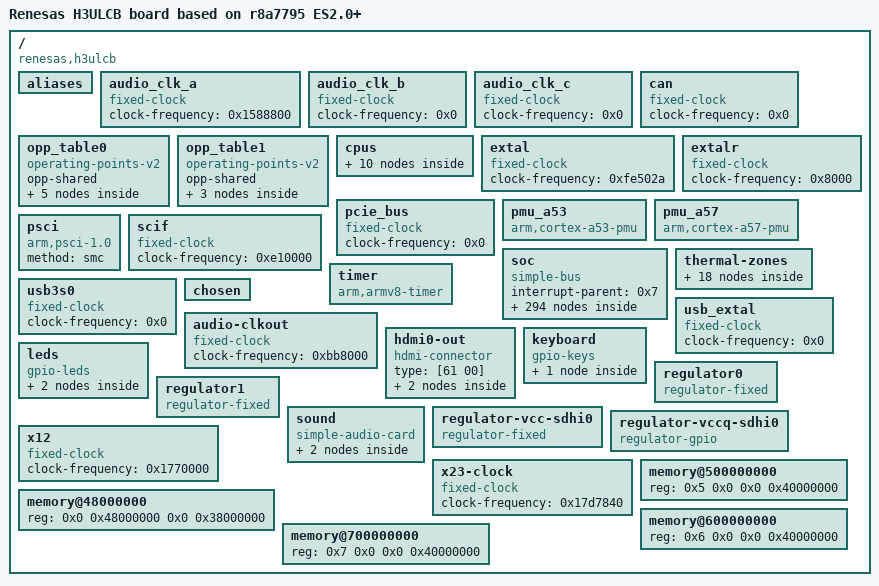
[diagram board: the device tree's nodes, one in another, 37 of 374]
/*
 * The code contained herein is licensed under the GNU General Public
 * License. You may obtain a copy of the GNU General Public License
 * Version 2 or later at the following locations:
 *
 * http://www.opensource.org/licenses/gpl-license.html
 * http://www.gnu.org/copyleft/gpl.html
 *
 * @TAG(OTHER_GPL)
 */

/dts-v1/;

/ {
	compatible = "renesas,h3ulcb", "renesas,r8a7795";
	#address-cells = <0x2>;
	#size-cells = <0x2>;
	model = "Renesas H3ULCB board based on r8a7795 ES2.0+";

	aliases {
		i2c0 = "/soc/i2c@e6500000";
		i2c1 = "/soc/i2c@e6508000";
		i2c2 = "/soc/i2c@e6510000";
		i2c3 = "/soc/i2c@e66d0000";
		i2c4 = "/soc/i2c@e66d8000";
		i2c5 = "/soc/i2c@e66e0000";
		i2c6 = "/soc/i2c@e66e8000";
		i2c7 = "/soc/i2c@e60b0000";
		serial0 = "/soc/serial@e6e88000";
		ethernet0 = "/soc/ethernet@e6800000";
	};

	audio_clk_a {
		compatible = "fixed-clock";
		#clock-cells = <0x0>;
		clock-frequency = <0x1588800>;
		phandle = <0x48>;
	};

	audio_clk_b {
		compatible = "fixed-clock";
		#clock-cells = <0x0>;
		clock-frequency = <0x0>;
	};

	audio_clk_c {
		compatible = "fixed-clock";
		#clock-cells = <0x0>;
		clock-frequency = <0x0>;
		phandle = <0x49>;
	};

	can {
		compatible = "fixed-clock";
		#clock-cells = <0x0>;
		clock-frequency = <0x0>;
		phandle = <0x2e>;
	};

	opp_table0 {
		compatible = "operating-points-v2";
		opp-shared;
		phandle = <0x4>;

		opp-500000000 {
			opp-hz = <0x0 0x1dcd6500>;
			opp-microvolt = <0xcaa30>;
			clock-latency-ns = <0x493e0>;
		};

		opp-1000000000 {
			opp-hz = <0x0 0x3b9aca00>;
			opp-microvolt = <0xcaa30>;
			clock-latency-ns = <0x493e0>;
		};

		opp-1500000000 {
			opp-hz = <0x0 0x59682f00>;
			opp-microvolt = <0xcaa30>;
			clock-latency-ns = <0x493e0>;
			opp-suspend;
		};

		opp-1600000000 {
			opp-hz = <0x0 0x5f5e1000>;
			opp-microvolt = <0xdbba0>;
			clock-latency-ns = <0x493e0>;
			turbo-mode;
		};

		opp-1700000000 {
			opp-hz = <0x0 0x6553f100>;
			opp-microvolt = <0xea600>;
			clock-latency-ns = <0x493e0>;
			turbo-mode;
		};
	};

	opp_table1 {
		compatible = "operating-points-v2";
		opp-shared;
		phandle = <0x6>;

		opp-800000000 {
			opp-hz = <0x0 0x2faf0800>;
			opp-microvolt = <0xc8320>;
			clock-latency-ns = <0x493e0>;
		};

		opp-1000000000 {
			opp-hz = <0x0 0x3b9aca00>;
			opp-microvolt = <0xc8320>;
			clock-latency-ns = <0x493e0>;
		};

		opp-1200000000 {
			opp-hz = <0x0 0x47868c00>;
			opp-microvolt = <0xc8320>;
			clock-latency-ns = <0x493e0>;
		};
	};

	cpus {
		#address-cells = <0x1>;
		#size-cells = <0x0>;

		cpu@0 {
			compatible = "arm,cortex-a57", "arm,armv8";
			reg = <0x0>;
			device_type = "cpu";
			power-domains = <0x1 0x0>;
			next-level-cache = <0x2>;
			enable-method = "psci";
			clocks = <0x3 0x0 0x0>;
			operating-points-v2 = <0x4>;
			#cooling-cells = <0x2>;
			phandle = <0xc>;
		};

		cpu@1 {
			compatible = "arm,cortex-a57", "arm,armv8";
			reg = <0x1>;
			device_type = "cpu";
			power-domains = <0x1 0x1>;
			next-level-cache = <0x2>;
			enable-method = "psci";
			clocks = <0x3 0x0 0x0>;
			operating-points-v2 = <0x4>;
			#cooling-cells = <0x2>;
			phandle = <0xd>;
		};

		cpu@2 {
			compatible = "arm,cortex-a57", "arm,armv8";
			reg = <0x2>;
			device_type = "cpu";
			power-domains = <0x1 0x2>;
			next-level-cache = <0x2>;
			enable-method = "psci";
			clocks = <0x3 0x0 0x0>;
			operating-points-v2 = <0x4>;
			#cooling-cells = <0x2>;
			phandle = <0xe>;
		};

		cpu@3 {
			compatible = "arm,cortex-a57", "arm,armv8";
			reg = <0x3>;
			device_type = "cpu";
			power-domains = <0x1 0x3>;
			next-level-cache = <0x2>;
			enable-method = "psci";
			clocks = <0x3 0x0 0x0>;
			operating-points-v2 = <0x4>;
			#cooling-cells = <0x2>;
			phandle = <0xf>;
		};

		cpu@100 {
			compatible = "arm,cortex-a53", "arm,armv8";
			reg = <0x100>;
			device_type = "cpu";
			power-domains = <0x1 0x5>;
			next-level-cache = <0x5>;
			enable-method = "psci";
			clocks = <0x3 0x0 0x1>;
			operating-points-v2 = <0x6>;
			phandle = <0x8>;
		};

		cpu@101 {
			compatible = "arm,cortex-a53", "arm,armv8";
			reg = <0x101>;
			device_type = "cpu";
			power-domains = <0x1 0x6>;
			next-level-cache = <0x5>;
			enable-method = "psci";
			clocks = <0x3 0x0 0x1>;
			operating-points-v2 = <0x6>;
			phandle = <0x9>;
		};

		cpu@102 {
			compatible = "arm,cortex-a53", "arm,armv8";
			reg = <0x102>;
			device_type = "cpu";
			power-domains = <0x1 0x7>;
			next-level-cache = <0x5>;
			enable-method = "psci";
			clocks = <0x3 0x0 0x1>;
			operating-points-v2 = <0x6>;
			phandle = <0xa>;
		};

		cpu@103 {
			compatible = "arm,cortex-a53", "arm,armv8";
			reg = <0x103>;
			device_type = "cpu";
			power-domains = <0x1 0x8>;
			next-level-cache = <0x5>;
			enable-method = "psci";
			clocks = <0x3 0x0 0x1>;
			operating-points-v2 = <0x6>;
			phandle = <0xb>;
		};

		cache-controller-0 {
			compatible = "cache";
			power-domains = <0x1 0xc>;
			cache-unified;
			cache-level = <0x2>;
			phandle = <0x2>;
		};

		cache-controller-1 {
			compatible = "cache";
			power-domains = <0x1 0x15>;
			cache-unified;
			cache-level = <0x2>;
			phandle = <0x5>;
		};
	};

	extal {
		compatible = "fixed-clock";
		#clock-cells = <0x0>;
		clock-frequency = <0xfe502a>;
		phandle = <0x12>;
	};

	extalr {
		compatible = "fixed-clock";
		#clock-cells = <0x0>;
		clock-frequency = <0x8000>;
		phandle = <0x13>;
	};

	pcie_bus {
		compatible = "fixed-clock";
		#clock-cells = <0x0>;
		clock-frequency = <0x0>;
		phandle = <0x66>;
	};

	pmu_a53 {
		compatible = "arm,cortex-a53-pmu";
		interrupts-extended = <0x7 0x0 0x54 0x4 0x7 0x0 0x55 0x4 0x7 0x0 0x56 0x4 0x7 0x0 0x57 0x4>;
		interrupt-affinity = <0x8 0x9 0xa 0xb>;
	};

	pmu_a57 {
		compatible = "arm,cortex-a57-pmu";
		interrupts-extended = <0x7 0x0 0x48 0x4 0x7 0x0 0x49 0x4 0x7 0x0 0x4a 0x4 0x7 0x0 0x4b 0x4>;
		interrupt-affinity = <0xc 0xd 0xe 0xf>;
	};

	psci {
		compatible = "arm,psci-1.0", "arm,psci-0.2";
		method = "smc";
	};

	scif {
		compatible = "fixed-clock";
		#clock-cells = <0x0>;
		clock-frequency = <0xe10000>;
		phandle = <0x1f>;
	};

	soc {
		compatible = "simple-bus";
		interrupt-parent = <0x7>;
		#address-cells = <0x2>;
		#size-cells = <0x2>;
		ranges;

		watchdog@e6020000 {
			compatible = "renesas,r8a7795-wdt", "renesas,rcar-gen3-wdt";
			reg = <0x0 0xe6020000 0x0 0xc>;
			clocks = <0x3 0x1 0x192>;
			power-domains = <0x1 0x20>;
			resets = <0x3 0x192>;
			status = "okay";
			timeout-sec = <0x3c>;
		};

		gpio@e6050000 {
			compatible = "renesas,gpio-r8a7795", "renesas,rcar-gen3-gpio";
			reg = <0x0 0xe6050000 0x0 0x50>;
			interrupts = <0x0 0x4 0x4>;
			#gpio-cells = <0x2>;
			gpio-controller;
			gpio-ranges = <0x10 0x0 0x0 0x10>;
			#interrupt-cells = <0x2>;
			interrupt-controller;
			clocks = <0x3 0x1 0x390>;
			power-domains = <0x1 0x20>;
			resets = <0x3 0x390>;
		};

		gpio@e6051000 {
			compatible = "renesas,gpio-r8a7795", "renesas,rcar-gen3-gpio";
			reg = <0x0 0xe6051000 0x0 0x50>;
			interrupts = <0x0 0x5 0x4>;
			#gpio-cells = <0x2>;
			gpio-controller;
			gpio-ranges = <0x10 0x0 0x20 0x1d>;
			#interrupt-cells = <0x2>;
			interrupt-controller;
			clocks = <0x3 0x1 0x38f>;
			power-domains = <0x1 0x20>;
			resets = <0x3 0x38f>;
		};

		gpio@e6052000 {
			compatible = "renesas,gpio-r8a7795", "renesas,rcar-gen3-gpio";
			reg = <0x0 0xe6052000 0x0 0x50>;
			interrupts = <0x0 0x6 0x4>;
			#gpio-cells = <0x2>;
			gpio-controller;
			gpio-ranges = <0x10 0x0 0x40 0xf>;
			#interrupt-cells = <0x2>;
			interrupt-controller;
			clocks = <0x3 0x1 0x38e>;
			power-domains = <0x1 0x20>;
			resets = <0x3 0x38e>;
			phandle = <0x2d>;
		};

		gpio@e6053000 {
			compatible = "renesas,gpio-r8a7795", "renesas,rcar-gen3-gpio";
			reg = <0x0 0xe6053000 0x0 0x50>;
			interrupts = <0x0 0x7 0x4>;
			#gpio-cells = <0x2>;
			gpio-controller;
			gpio-ranges = <0x10 0x0 0x60 0x10>;
			#interrupt-cells = <0x2>;
			interrupt-controller;
			clocks = <0x3 0x1 0x38d>;
			power-domains = <0x1 0x20>;
			resets = <0x3 0x38d>;
			phandle = <0x60>;
		};

		gpio@e6054000 {
			compatible = "renesas,gpio-r8a7795", "renesas,rcar-gen3-gpio";
			reg = <0x0 0xe6054000 0x0 0x50>;
			interrupts = <0x0 0x8 0x4>;
			#gpio-cells = <0x2>;
			gpio-controller;
			gpio-ranges = <0x10 0x0 0x80 0x12>;
			#interrupt-cells = <0x2>;
			interrupt-controller;
			clocks = <0x3 0x1 0x38c>;
			power-domains = <0x1 0x20>;
			resets = <0x3 0x38c>;
		};

		gpio@e6055000 {
			compatible = "renesas,gpio-r8a7795", "renesas,rcar-gen3-gpio";
			reg = <0x0 0xe6055000 0x0 0x50>;
			interrupts = <0x0 0x9 0x4>;
			#gpio-cells = <0x2>;
			gpio-controller;
			gpio-ranges = <0x10 0x0 0xa0 0x1a>;
			#interrupt-cells = <0x2>;
			interrupt-controller;
			clocks = <0x3 0x1 0x38b>;
			power-domains = <0x1 0x20>;
			resets = <0x3 0x38b>;
			phandle = <0x97>;
		};

		gpio@e6055400 {
			compatible = "renesas,gpio-r8a7795", "renesas,rcar-gen3-gpio";
			reg = <0x0 0xe6055400 0x0 0x50>;
			interrupts = <0x0 0xa 0x4>;
			#gpio-cells = <0x2>;
			gpio-controller;
			gpio-ranges = <0x10 0x0 0xc0 0x20>;
			#interrupt-cells = <0x2>;
			interrupt-controller;
			clocks = <0x3 0x1 0x38a>;
			power-domains = <0x1 0x20>;
			resets = <0x3 0x38a>;
			phandle = <0x94>;
		};

		gpio@e6055800 {
			compatible = "renesas,gpio-r8a7795", "renesas,rcar-gen3-gpio";
			reg = <0x0 0xe6055800 0x0 0x50>;
			interrupts = <0x0 0xb 0x4>;
			#gpio-cells = <0x2>;
			gpio-controller;
			gpio-ranges = <0x10 0x0 0xe0 0x4>;
			#interrupt-cells = <0x2>;
			interrupt-controller;
			clocks = <0x3 0x1 0x389>;
			power-domains = <0x1 0x20>;
			resets = <0x3 0x389>;
		};

		pin-controller@e6060000 {
			compatible = "renesas,pfc-r8a7795";
			reg = <0x0 0xe6060000 0x0 0x50c>;
			pinctrl-0 = <0x11>;
			pinctrl-names = "default";
			phandle = <0x10>;

			avb {
				phandle = <0x2b>;

				mux {
					groups = "avb_link", "avb_mdio", "avb_mii";
					function = "avb";
				};

				pins_mdio {
					groups = "avb_mdio";
					drive-strength = <0x18>;
				};

				pins_mii_tx {
					pins = "PIN_AVB_TX_CTL", "PIN_AVB_TXC", "PIN_AVB_TD0", "PIN_AVB_TD1", "PIN_AVB_TD2", "PIN_AVB_TD3";
					drive-strength = <0xc>;
				};
			};

			i2c2 {
				groups = "i2c2_a";
				function = "i2c2";
				phandle = <0x16>;
			};

			irq0 {
				groups = "intc_ex_irq0";
				function = "intc_ex";
				phandle = <0x1d>;
			};

			scif2 {
				groups = "scif2_data_a";
				function = "scif2";
				phandle = <0x2f>;
			};

			scif_clk {
				groups = "scif_clk_a";
				function = "scif_clk";
				phandle = <0x11>;
			};

			sd0 {
				groups = "sdhi0_data4", "sdhi0_ctrl";
				function = "sdhi0";
				power-source = <0xce4>;
				phandle = <0x5c>;
			};

			sd0_uhs {
				groups = "sdhi0_data4", "sdhi0_ctrl";
				function = "sdhi0";
				power-source = <0x708>;
				phandle = <0x5d>;
			};

			sd2 {
				groups = "sdhi2_data8", "sdhi2_ctrl", "sdhi2_ds";
				function = "sdhi2";
				power-source = <0xce4>;
				phandle = <0x61>;
			};

			sd2_uhs {
				groups = "sdhi2_data8", "sdhi2_ctrl", "sdhi2_ds";
				function = "sdhi2";
				power-source = <0x708>;
				phandle = <0x62>;
			};

			sound {
				groups = "ssi01239_ctrl", "ssi0_data", "ssi1_data_a";
				function = "ssi";
				phandle = <0x4a>;
			};

			sound-clk {
				groups = "audio_clk_a_a", "audio_clk_b_a", "audio_clk_c_a", "audio_clkout_a", "audio_clkout3_a";
				function = "audio_clk";
				phandle = <0x4b>;
			};

			usb1 {
				groups = "usb1";
				function = "usb1";
				phandle = <0x5b>;
			};
		};

		clock-controller@e6150000 {
			compatible = "renesas,r8a7795-cpg-mssr";
			reg = <0x0 0xe6150000 0x0 0x1000>;
			clocks = <0x12 0x13>;
			clock-names = "extal", "extalr";
			#clock-cells = <0x2>;
			#power-domain-cells = <0x0>;
			#reset-cells = <0x1>;
			phandle = <0x3>;
		};

		reset-controller@e6160000 {
			compatible = "renesas,r8a7795-rst";
			reg = <0x0 0xe6160000 0x0 0x200>;
		};

		system-controller@e6180000 {
			compatible = "renesas,r8a7795-sysc";
			reg = <0x0 0xe6180000 0x0 0x400>;
			#power-domain-cells = <0x1>;
			phandle = <0x1>;
		};

		thermal@e6198000 {
			compatible = "renesas,r8a7795-thermal";
			reg = <0x0 0xe6198000 0x0 0x100 0x0 0xe61a0000 0x0 0x100 0x0 0xe61a8000 0x0 0x100>;
			interrupts = <0x0 0x43 0x4 0x0 0x44 0x4 0x0 0x45 0x4>;
			clocks = <0x3 0x1 0x20a>;
			power-domains = <0x1 0x20>;
			resets = <0x3 0x20a>;
			#thermal-sensor-cells = <0x1>;
			phandle = <0x8f>;
		};

		interrupt-controller@e61c0000 {
			compatible = "renesas,intc-ex-r8a7795", "renesas,irqc";
			#interrupt-cells = <0x2>;
			interrupt-controller;
			reg = <0x0 0xe61c0000 0x0 0x200>;
			interrupts = <0x0 0x0 0x4 0x0 0x1 0x4 0x0 0x2 0x4 0x0 0x3 0x4 0x0 0x12 0x4 0x0 0xa1 0x4>;
			clocks = <0x3 0x1 0x197>;
			power-domains = <0x1 0x20>;
			resets = <0x3 0x197>;
			phandle = <0x1e>;
		};

		i2c@e6500000 {
			#address-cells = <0x1>;
			#size-cells = <0x0>;
			compatible = "renesas,i2c-r8a7795", "renesas,rcar-gen3-i2c";
			reg = <0x0 0xe6500000 0x0 0x40>;
			interrupts = <0x0 0x11f 0x4>;
			clocks = <0x3 0x1 0x3a3>;
			power-domains = <0x1 0x20>;
			resets = <0x3 0x3a3>;
			dmas = <0x14 0x91 0x14 0x90 0x15 0x91 0x15 0x90>;
			dma-names = "tx", "rx", "tx", "rx";
			i2c-scl-internal-delay-ns = <0x6e>;
			status = "disabled";
		};

		i2c@e6508000 {
			#address-cells = <0x1>;
			#size-cells = <0x0>;
			compatible = "renesas,i2c-r8a7795", "renesas,rcar-gen3-i2c";
			reg = <0x0 0xe6508000 0x0 0x40>;
			interrupts = <0x0 0x120 0x4>;
			clocks = <0x3 0x1 0x3a2>;
			power-domains = <0x1 0x20>;
			resets = <0x3 0x3a2>;
			dmas = <0x14 0x93 0x14 0x92 0x15 0x93 0x15 0x92>;
			dma-names = "tx", "rx", "tx", "rx";
			i2c-scl-internal-delay-ns = <0x6>;
			status = "disabled";
		};

		i2c@e6510000 {
			#address-cells = <0x1>;
			#size-cells = <0x0>;
			compatible = "renesas,i2c-r8a7795", "renesas,rcar-gen3-i2c";
			reg = <0x0 0xe6510000 0x0 0x40>;
			interrupts = <0x0 0x11e 0x4>;
			clocks = <0x3 0x1 0x3a1>;
			power-domains = <0x1 0x20>;
			resets = <0x3 0x3a1>;
			dmas = <0x14 0x95 0x14 0x94 0x15 0x95 0x15 0x94>;
			dma-names = "tx", "rx", "tx", "rx";
			i2c-scl-internal-delay-ns = <0x6>;
			status = "okay";
			pinctrl-0 = <0x16>;
			pinctrl-names = "default";
			clock-frequency = <0x186a0>;

			codec@10 {
				compatible = "asahi-kasei,ak4613";
				#sound-dai-cells = <0x0>;
				reg = <0x10>;
				clocks = <0x17 0x3>;
				asahi-kasei,in1-single-end;
				asahi-kasei,in2-single-end;
				asahi-kasei,out1-single-end;
				asahi-kasei,out2-single-end;
				asahi-kasei,out3-single-end;
				asahi-kasei,out4-single-end;
				asahi-kasei,out5-single-end;
				asahi-kasei,out6-single-end;
				phandle = <0x96>;
			};

			clk-multiplier@4f {
				#clock-cells = <0x0>;
				compatible = "cirrus,cs2000-cp";
				reg = <0x4f>;
				clocks = <0x18 0x19>;
				clock-names = "clk_in", "ref_clk";
				assigned-clocks = <0x1a>;
				assigned-clock-rates = <0x1770000>;
				phandle = <0x1a>;
			};
		};

		i2c@e66d0000 {
			#address-cells = <0x1>;
			#size-cells = <0x0>;
			compatible = "renesas,i2c-r8a7795", "renesas,rcar-gen3-i2c";
			reg = <0x0 0xe66d0000 0x0 0x40>;
			interrupts = <0x0 0x122 0x4>;
			clocks = <0x3 0x1 0x3a0>;
			power-domains = <0x1 0x20>;
			resets = <0x3 0x3a0>;
			dmas = <0x1b 0x97 0x1b 0x96>;
			dma-names = "tx", "rx";
			i2c-scl-internal-delay-ns = <0x6e>;
			status = "disabled";
		};

		i2c@e66d8000 {
			#address-cells = <0x1>;
			#size-cells = <0x0>;
			compatible = "renesas,i2c-r8a7795", "renesas,rcar-gen3-i2c";
			reg = <0x0 0xe66d8000 0x0 0x40>;
			interrupts = <0x0 0x13 0x4>;
			clocks = <0x3 0x1 0x39f>;
			power-domains = <0x1 0x20>;
			resets = <0x3 0x39f>;
			dmas = <0x1b 0x99 0x1b 0x98>;
			dma-names = "tx", "rx";
			i2c-scl-internal-delay-ns = <0x6e>;
			status = "okay";
			clock-frequency = <0x61a80>;

			clock-generator@6a {
				compatible = "idt,5p49v5925";
				reg = <0x6a>;
				#clock-cells = <0x1>;
				clocks = <0x1c>;
				clock-names = "xin";
				phandle = <0x87>;
			};
		};

		i2c@e66e0000 {
			#address-cells = <0x1>;
			#size-cells = <0x0>;
			compatible = "renesas,i2c-r8a7795", "renesas,rcar-gen3-i2c";
			reg = <0x0 0xe66e0000 0x0 0x40>;
			interrupts = <0x0 0x14 0x4>;
			clocks = <0x3 0x1 0x397>;
			power-domains = <0x1 0x20>;
			resets = <0x3 0x397>;
			dmas = <0x1b 0x9b 0x1b 0x9a>;
			dma-names = "tx", "rx";
			i2c-scl-internal-delay-ns = <0x6e>;
			status = "disabled";
		};

		i2c@e66e8000 {
			#address-cells = <0x1>;
			#size-cells = <0x0>;
			compatible = "renesas,i2c-r8a7795", "renesas,rcar-gen3-i2c";
			reg = <0x0 0xe66e8000 0x0 0x40>;
			interrupts = <0x0 0x15 0x4>;
			clocks = <0x3 0x1 0x396>;
			power-domains = <0x1 0x20>;
			resets = <0x3 0x396>;
			dmas = <0x1b 0x9d 0x1b 0x9c>;
			dma-names = "tx", "rx";
			i2c-scl-internal-delay-ns = <0x6>;
			status = "disabled";
		};

		i2c@e60b0000 {
			#address-cells = <0x1>;
			#size-cells = <0x0>;
			compatible = "renesas,iic-r8a7795", "renesas,rcar-gen3-iic", "renesas,rmobile-iic";
			reg = <0x0 0xe60b0000 0x0 0x425>;
			interrupts = <0x0 0xad 0x4>;
			clocks = <0x3 0x1 0x39e>;
			power-domains = <0x1 0x20>;
			resets = <0x3 0x39e>;
			dmas = <0x1b 0x11 0x1b 0x10>;
			dma-names = "tx", "rx";
			status = "okay";
			clock-frequency = <0x61a80>;

			pmic@30 {
				pinctrl-0 = <0x1d>;
				pinctrl-names = "default";
				compatible = "rohm,bd9571mwv";
				reg = <0x30>;
				interrupt-parent = <0x1e>;
				interrupts = <0x0 0x8>;
				interrupt-controller;
				#interrupt-cells = <0x2>;
				gpio-controller;
				#gpio-cells = <0x2>;
				rohm,ddr-backup-power = <0xf>;
				rohm,rstbmode-pulse;

				regulators {

					dvfs {
						regulator-name = "dvfs";
						regulator-min-microvolt = <0xb71b0>;
						regulator-max-microvolt = <0xfb770>;
						regulator-boot-on;
						regulator-always-on;
					};
				};
			};
		};

		serial@e6540000 {
			compatible = "renesas,hscif-r8a7795", "renesas,rcar-gen3-hscif", "renesas,hscif";
			reg = <0x0 0xe6540000 0x0 0x60>;
			interrupts = <0x0 0x9a 0x4>;
			clocks = <0x3 0x1 0x208 0x3 0x0 0x10 0x1f>;
			clock-names = "fck", "brg_int", "scif_clk";
			dmas = <0x14 0x31 0x14 0x30 0x15 0x31 0x15 0x30>;
			dma-names = "tx", "rx", "tx", "rx";
			power-domains = <0x1 0x20>;
			resets = <0x3 0x208>;
			status = "disabled";
		};

		serial@e6550000 {
			compatible = "renesas,hscif-r8a7795", "renesas,rcar-gen3-hscif", "renesas,hscif";
			reg = <0x0 0xe6550000 0x0 0x60>;
			interrupts = <0x0 0x9b 0x4>;
			clocks = <0x3 0x1 0x207 0x3 0x0 0x10 0x1f>;
			clock-names = "fck", "brg_int", "scif_clk";
			dmas = <0x14 0x33 0x14 0x32 0x15 0x33 0x15 0x32>;
			dma-names = "tx", "rx", "tx", "rx";
			power-domains = <0x1 0x20>;
			resets = <0x3 0x207>;
			status = "disabled";
		};

		serial@e6560000 {
			compatible = "renesas,hscif-r8a7795", "renesas,rcar-gen3-hscif", "renesas,hscif";
			reg = <0x0 0xe6560000 0x0 0x60>;
			interrupts = <0x0 0x90 0x4>;
			clocks = <0x3 0x1 0x206 0x3 0x0 0x10 0x1f>;
			clock-names = "fck", "brg_int", "scif_clk";
			dmas = <0x14 0x35 0x14 0x34 0x15 0x35 0x15 0x34>;
			dma-names = "tx", "rx", "tx", "rx";
			power-domains = <0x1 0x20>;
			resets = <0x3 0x206>;
			status = "disabled";
		};

		serial@e66a0000 {
			compatible = "renesas,hscif-r8a7795", "renesas,rcar-gen3-hscif", "renesas,hscif";
			reg = <0x0 0xe66a0000 0x0 0x60>;
			interrupts = <0x0 0x91 0x4>;
			clocks = <0x3 0x1 0x205 0x3 0x0 0x10 0x1f>;
			clock-names = "fck", "brg_int", "scif_clk";
			dmas = <0x1b 0x37 0x1b 0x36>;
			dma-names = "tx", "rx";
			power-domains = <0x1 0x20>;
			resets = <0x3 0x205>;
			status = "disabled";
		};

		serial@e66b0000 {
			compatible = "renesas,hscif-r8a7795", "renesas,rcar-gen3-hscif", "renesas,hscif";
			reg = <0x0 0xe66b0000 0x0 0x60>;
			interrupts = <0x0 0x92 0x4>;
			clocks = <0x3 0x1 0x204 0x3 0x0 0x10 0x1f>;
			clock-names = "fck", "brg_int", "scif_clk";
			dmas = <0x1b 0x39 0x1b 0x38>;
			dma-names = "tx", "rx";
			power-domains = <0x1 0x20>;
			resets = <0x3 0x204>;
			status = "disabled";
		};

		usb@e6590000 {
			compatible = "renesas,usbhs-r8a7795", "renesas,rcar-gen3-usbhs";
			reg = <0x0 0xe6590000 0x0 0x100>;
			interrupts = <0x0 0x6b 0x4>;
			clocks = <0x3 0x1 0x2c0 0x3 0x1 0x2bf>;
			dmas = <0x20 0x0 0x20 0x1 0x21 0x0 0x21 0x1>;
			dma-names = "ch0", "ch1", "ch2", "ch3";
			renesas,buswait = <0xb>;
			phys = <0x22>;
			phy-names = "usb";
			power-domains = <0x1 0x20>;
			resets = <0x3 0x2c0 0x3 0x2bf>;
			status = "disabled";
		};

		usb@e659c000 {
			compatible = "renesas,usbhs-r8a7795", "renesas,rcar-gen3-usbhs";
			reg = <0x0 0xe659c000 0x0 0x100>;
			interrupts = <0x0 0x25 0x4>;
			clocks = <0x3 0x1 0x2c1 0x3 0x1 0x2bc>;
			dmas = <0x23 0x0 0x23 0x1 0x24 0x0 0x24 0x1>;
			dma-names = "ch0", "ch1", "ch2", "ch3";
			renesas,buswait = <0xb>;
			phys = <0x25>;
			phy-names = "usb";
			power-domains = <0x1 0x20>;
			resets = <0x3 0x2c1 0x3 0x2bc>;
			status = "disabled";
		};

		dma-controller@e65a0000 {
			compatible = "renesas,r8a7795-usb-dmac", "renesas,usb-dmac";
			reg = <0x0 0xe65a0000 0x0 0x100>;
			interrupts = <0x0 0x6d 0x4 0x0 0x6d 0x4>;
			interrupt-names = "ch0", "ch1";
			clocks = <0x3 0x1 0x14a>;
			power-domains = <0x1 0x20>;
			resets = <0x3 0x14a>;
			#dma-cells = <0x1>;
			dma-channels = <0x2>;
			phandle = <0x20>;
		};

		dma-controller@e65b0000 {
			compatible = "renesas,r8a7795-usb-dmac", "renesas,usb-dmac";
			reg = <0x0 0xe65b0000 0x0 0x100>;
			interrupts = <0x0 0x6e 0x4 0x0 0x6e 0x4>;
			interrupt-names = "ch0", "ch1";
			clocks = <0x3 0x1 0x14b>;
			power-domains = <0x1 0x20>;
			resets = <0x3 0x14b>;
			#dma-cells = <0x1>;
			dma-channels = <0x2>;
			phandle = <0x21>;
		};

		dma-controller@e6460000 {
			compatible = "renesas,r8a7795-usb-dmac", "renesas,usb-dmac";
			reg = <0x0 0xe6460000 0x0 0x100>;
			interrupts = <0x0 0x22 0x4 0x0 0x22 0x4>;
			interrupt-names = "ch0", "ch1";
			clocks = <0x3 0x1 0x146>;
			power-domains = <0x1 0x20>;
			resets = <0x3 0x146>;
			#dma-cells = <0x1>;
			dma-channels = <0x2>;
			phandle = <0x23>;
		};

		dma-controller@e6470000 {
			compatible = "renesas,r8a7795-usb-dmac", "renesas,usb-dmac";
			reg = <0x0 0xe6470000 0x0 0x100>;
			interrupts = <0x0 0x23 0x4 0x0 0x23 0x4>;
			interrupt-names = "ch0", "ch1";
			clocks = <0x3 0x1 0x149>;
			power-domains = <0x1 0x20>;
			resets = <0x3 0x149>;
			#dma-cells = <0x1>;
			dma-channels = <0x2>;
			phandle = <0x24>;
		};

		usb-phy@e65ee000 {
			compatible = "renesas,r8a7795-usb3-phy", "renesas,rcar-gen3-usb3-phy";
			reg = <0x0 0xe65ee000 0x0 0x90>;
			clocks = <0x3 0x1 0x148 0x26 0x27>;
			clock-names = "usb3-if", "usb3s_clk", "usb_extal";
			power-domains = <0x1 0x20>;
			resets = <0x3 0x148>;
			#phy-cells = <0x0>;
			status = "disabled";
		};

		crypto@e6601000 {
			compatible = "arm,cryptocell-630p-ree";
			interrupts = <0x0 0x47 0x4>;
			reg = <0x0 0xe6601000 0x0 0x1000>;
			clocks = <0x3 0x1 0xe5>;
			resets = <0x3 0xe5>;
			power-domains = <0x1 0x20>;
		};

		dma-controller@e6700000 {
			compatible = "renesas,dmac-r8a7795", "renesas,rcar-dmac";
			reg = <0x0 0xe6700000 0x0 0x10000>;
			interrupts = <0x0 0xc7 0x4 0x0 0xc8 0x4 0x0 0xc9 0x4 0x0 0xca 0x4 0x0 0xcb 0x4 0x0 0xcc 0x4 0x0 0xcd 0x4 0x0 0xce 0x4 0x0 0xcf 0x4 0x0 0xd0 0x4 0x0 0xd1 0x4 0x0 0xd2 0x4 0x0 0xd3 0x4 0x0 0xd4 0x4 0x0 0xd5 0x4 0x0 0xd6 0x4 0x0 0xd7 0x4>;
			interrupt-names = "error", "ch0", "ch1", "ch2", "ch3", "ch4", "ch5", "ch6", "ch7", "ch8", "ch9", "ch10", "ch11", "ch12", "ch13", "ch14", "ch15";
			clocks = <0x3 0x1 0xdb>;
			clock-names = "fck";
			power-domains = <0x1 0x20>;
			resets = <0x3 0xdb>;
			#dma-cells = <0x1>;
			dma-channels = <0x10>;
			iommus = <0x28 0x0 0x28 0x1 0x28 0x2 0x28 0x3 0x28 0x4 0x28 0x5 0x28 0x6 0x28 0x7 0x28 0x8 0x28 0x9 0x28 0xa 0x28 0xb 0x28 0xc 0x28 0xd 0x28 0xe 0x28 0xf>;
			phandle = <0x1b>;
		};

		dma-controller@e7300000 {
			compatible = "renesas,dmac-r8a7795", "renesas,rcar-dmac";
			reg = <0x0 0xe7300000 0x0 0x10000>;
			interrupts = <0x0 0xdc 0x4 0x0 0xd8 0x4 0x0 0xd9 0x4 0x0 0xda 0x4 0x0 0xdb 0x4 0x0 0x134 0x4 0x0 0x135 0x4 0x0 0x136 0x4 0x0 0x137 0x4 0x0 0x138 0x4 0x0 0x139 0x4 0x0 0x13a 0x4 0x0 0x13b 0x4 0x0 0x13c 0x4 0x0 0x13d 0x4 0x0 0x13e 0x4 0x0 0x13f 0x4>;
			interrupt-names = "error", "ch0", "ch1", "ch2", "ch3", "ch4", "ch5", "ch6", "ch7", "ch8", "ch9", "ch10", "ch11", "ch12", "ch13", "ch14", "ch15";
			clocks = <0x3 0x1 0xda>;
			clock-names = "fck";
			power-domains = <0x1 0x20>;
			resets = <0x3 0xda>;
			#dma-cells = <0x1>;
			dma-channels = <0x10>;
			iommus = <0x29 0x0 0x29 0x1 0x29 0x2 0x29 0x3 0x29 0x4 0x29 0x5 0x29 0x6 0x29 0x7 0x29 0x8 0x29 0x9 0x29 0xa 0x29 0xb 0x29 0xc 0x29 0xd 0x29 0xe 0x29 0xf>;
			phandle = <0x14>;
		};

		dma-controller@e7310000 {
			compatible = "renesas,dmac-r8a7795", "renesas,rcar-dmac";
			reg = <0x0 0xe7310000 0x0 0x10000>;
			interrupts = <0x0 0x1a0 0x4 0x0 0x1a1 0x4 0x0 0x1a2 0x4 0x0 0x1a3 0x4 0x0 0x1a4 0x4 0x0 0x1a5 0x4 0x0 0x1a6 0x4 0x0 0x1a7 0x4 0x0 0x1a8 0x4 0x0 0x1a9 0x4 0x0 0x1aa 0x4 0x0 0x1ab 0x4 0x0 0x1ac 0x4 0x0 0x1ad 0x4 0x0 0x1ae 0x4 0x0 0x1af 0x4 0x0 0x18d 0x4>;
			interrupt-names = "error", "ch0", "ch1", "ch2", "ch3", "ch4", "ch5", "ch6", "ch7", "ch8", "ch9", "ch10", "ch11", "ch12", "ch13", "ch14", "ch15";
			clocks = <0x3 0x1 0xd9>;
			clock-names = "fck";
			power-domains = <0x1 0x20>;
			resets = <0x3 0xd9>;
			#dma-cells = <0x1>;
			dma-channels = <0x10>;
			iommus = <0x29 0x10 0x29 0x11 0x29 0x12 0x29 0x13 0x29 0x14 0x29 0x15 0x29 0x16 0x29 0x17 0x29 0x18 0x29 0x19 0x29 0x1a 0x29 0x1b 0x29 0x1c 0x29 0x1d 0x29 0x1e 0x29 0x1f>;
			phandle = <0x15>;
		};

		mmu@e6740000 {
			compatible = "renesas,ipmmu-r8a7795";
			reg = <0x0 0xe6740000 0x0 0x1000>;
			renesas,ipmmu-main = <0x2a 0x0>;
			power-domains = <0x1 0x20>;
			#iommu-cells = <0x1>;
			phandle = <0x28>;
		};

		mmu@e7740000 {
			compatible = "renesas,ipmmu-r8a7795";
			reg = <0x0 0xe7740000 0x0 0x1000>;
			renesas,ipmmu-main = <0x2a 0x1>;
			power-domains = <0x1 0x20>;
			#iommu-cells = <0x1>;
			phandle = <0x29>;
		};

		mmu@e6570000 {
			compatible = "renesas,ipmmu-r8a7795";
			reg = <0x0 0xe6570000 0x0 0x1000>;
			renesas,ipmmu-main = <0x2a 0x2>;
			power-domains = <0x1 0x20>;
			#iommu-cells = <0x1>;
			phandle = <0x65>;
		};

		mmu@ff8b0000 {
			compatible = "renesas,ipmmu-r8a7795";
			reg = <0x0 0xff8b0000 0x0 0x1000>;
			renesas,ipmmu-main = <0x2a 0x3>;
			power-domains = <0x1 0x18>;
			#iommu-cells = <0x1>;
		};

		mmu@e67b0000 {
			compatible = "renesas,ipmmu-r8a7795";
			reg = <0x0 0xe67b0000 0x0 0x1000>;
			interrupts = <0x0 0xc4 0x4 0x0 0xc5 0x4>;
			power-domains = <0x1 0x20>;
			#iommu-cells = <0x1>;
			phandle = <0x2a>;
		};

		mmu@ec670000 {
			compatible = "renesas,ipmmu-r8a7795";
			reg = <0x0 0xec670000 0x0 0x1000>;
			renesas,ipmmu-main = <0x2a 0x4>;
			power-domains = <0x1 0x20>;
			#iommu-cells = <0x1>;
			phandle = <0x54>;
		};

		mmu@fd800000 {
			compatible = "renesas,ipmmu-r8a7795";
			reg = <0x0 0xfd800000 0x0 0x1000>;
			renesas,ipmmu-main = <0x2a 0x6>;
			power-domains = <0x1 0x20>;
			#iommu-cells = <0x1>;
		};

		mmu@fd950000 {
			compatible = "renesas,ipmmu-r8a7795";
			reg = <0x0 0xfd950000 0x0 0x1000>;
			renesas,ipmmu-main = <0x2a 0x7>;
			power-domains = <0x1 0x20>;
			#iommu-cells = <0x1>;
		};

		mmu@fd960000 {
			compatible = "renesas,ipmmu-r8a7795";
			reg = <0x0 0xfd960000 0x0 0x1000>;
			renesas,ipmmu-main = <0x2a 0x8>;
			power-domains = <0x1 0x20>;
			#iommu-cells = <0x1>;
		};

		mmu@fd970000 {
			compatible = "renesas,ipmmu-r8a7795";
			reg = <0x0 0xfd970000 0x0 0x1000>;
			renesas,ipmmu-main = <0x2a 0x9>;
			power-domains = <0x1 0x20>;
			#iommu-cells = <0x1>;
		};

		mmu@ffc80000 {
			compatible = "renesas,ipmmu-r8a7795";
			reg = <0x0 0xffc80000 0x0 0x1000>;
			renesas,ipmmu-main = <0x2a 0xa>;
			power-domains = <0x1 0x20>;
			#iommu-cells = <0x1>;
		};

		mmu@fe6b0000 {
			compatible = "renesas,ipmmu-r8a7795";
			reg = <0x0 0xfe6b0000 0x0 0x1000>;
			renesas,ipmmu-main = <0x2a 0xc>;
			power-domains = <0x1 0xe>;
			#iommu-cells = <0x1>;
		};

		mmu@fe6f0000 {
			compatible = "renesas,ipmmu-r8a7795";
			reg = <0x0 0xfe6f0000 0x0 0x1000>;
			renesas,ipmmu-main = <0x2a 0xd>;
			power-domains = <0x1 0xe>;
			#iommu-cells = <0x1>;
		};

		mmu@febd0000 {
			compatible = "renesas,ipmmu-r8a7795";
			reg = <0x0 0xfebd0000 0x0 0x1000>;
			renesas,ipmmu-main = <0x2a 0xe>;
			power-domains = <0x1 0x20>;
			#iommu-cells = <0x1>;
			phandle = <0x6b>;
		};

		mmu@febe0000 {
			compatible = "renesas,ipmmu-r8a7795";
			reg = <0x0 0xfebe0000 0x0 0x1000>;
			renesas,ipmmu-main = <0x2a 0xf>;
			power-domains = <0x1 0x20>;
			#iommu-cells = <0x1>;
			phandle = <0x6c>;
		};

		mmu@fe990000 {
			compatible = "renesas,ipmmu-r8a7795";
			reg = <0x0 0xfe990000 0x0 0x1000>;
			renesas,ipmmu-main = <0x2a 0x10>;
			power-domains = <0x1 0x9>;
			#iommu-cells = <0x1>;
			phandle = <0x69>;
		};

		mmu@fe980000 {
			compatible = "renesas,ipmmu-r8a7795";
			reg = <0x0 0xfe980000 0x0 0x1000>;
			renesas,ipmmu-main = <0x2a 0x11>;
			power-domains = <0x1 0x9>;
			#iommu-cells = <0x1>;
			phandle = <0x6a>;
		};

		ethernet@e6800000 {
			compatible = "renesas,etheravb-r8a7795", "renesas,etheravb-rcar-gen3";
			reg = <0x0 0xe6800000 0x0 0x800 0x0 0xe6a00000 0x0 0x10000>;
			interrupts = <0x0 0x27 0x4 0x0 0x28 0x4 0x0 0x29 0x4 0x0 0x2a 0x4 0x0 0x2b 0x4 0x0 0x2c 0x4 0x0 0x2d 0x4 0x0 0x2e 0x4 0x0 0x2f 0x4 0x0 0x30 0x4 0x0 0x31 0x4 0x0 0x32 0x4 0x0 0x33 0x4 0x0 0x34 0x4 0x0 0x35 0x4 0x0 0x36 0x4 0x0 0x37 0x4 0x0 0x38 0x4 0x0 0x39 0x4 0x0 0x3a 0x4 0x0 0x3b 0x4 0x0 0x3c 0x4 0x0 0x3d 0x4 0x0 0x3e 0x4 0x0 0x3f 0x4>;
			interrupt-names = "ch0", "ch1", "ch2", "ch3", "ch4", "ch5", "ch6", "ch7", "ch8", "ch9", "ch10", "ch11", "ch12", "ch13", "ch14", "ch15", "ch16", "ch17", "ch18", "ch19", "ch20", "ch21", "ch22", "ch23", "ch24";
			clocks = <0x3 0x1 0x32c>;
			power-domains = <0x1 0x20>;
			resets = <0x3 0x32c>;
			phy-mode = "rgmii-txid";
			iommus = <0x28 0x10>;
			#address-cells = <0x1>;
			#size-cells = <0x0>;
			status = "okay";
			pinctrl-0 = <0x2b>;
			pinctrl-names = "default";
			phy-handle = <0x2c>;

			ethernet-phy@0 {
				rxc-skew-ps = <0x5dc>;
				reg = <0x0>;
				interrupt-parent = <0x2d>;
				interrupts = <0xb 0x8>;
				reset-gpios = <0x2d 0xa 0x1>;
				phandle = <0x2c>;
			};
		};

		can@e6c30000 {
			compatible = "renesas,can-r8a7795", "renesas,rcar-gen3-can";
			reg = <0x0 0xe6c30000 0x0 0x1000>;
			interrupts = <0x0 0xba 0x4>;
			clocks = <0x3 0x1 0x394 0x3 0x0 0x27 0x2e>;
			clock-names = "clkp1", "clkp2", "can_clk";
			assigned-clocks = <0x3 0x0 0x27>;
			assigned-clock-rates = <0x2625a00>;
			power-domains = <0x1 0x20>;
			resets = <0x3 0x394>;
			status = "disabled";
		};

		can@e6c38000 {
			compatible = "renesas,can-r8a7795", "renesas,rcar-gen3-can";
			reg = <0x0 0xe6c38000 0x0 0x1000>;
			interrupts = <0x0 0xbb 0x4>;
			clocks = <0x3 0x1 0x393 0x3 0x0 0x27 0x2e>;
			clock-names = "clkp1", "clkp2", "can_clk";
			assigned-clocks = <0x3 0x0 0x27>;
			assigned-clock-rates = <0x2625a00>;
			power-domains = <0x1 0x20>;
			resets = <0x3 0x393>;
			status = "disabled";
		};

		can@e66c0000 {
			compatible = "renesas,r8a7795-canfd", "renesas,rcar-gen3-canfd";
			reg = <0x0 0xe66c0000 0x0 0x8000>;
			interrupts = <0x0 0x1d 0x4 0x0 0x1e 0x4>;
			clocks = <0x3 0x1 0x392 0x3 0x0 0x27 0x2e>;
			clock-names = "fck", "canfd", "can_clk";
			assigned-clocks = <0x3 0x0 0x27>;
			assigned-clock-rates = <0x2625a00>;
			power-domains = <0x1 0x20>;
			resets = <0x3 0x392>;
			status = "disabled";

			channel0 {
				status = "disabled";
			};

			channel1 {
				status = "disabled";
			};
		};

		pwm@e6e30000 {
			compatible = "renesas,pwm-r8a7795", "renesas,pwm-rcar";
			reg = <0x0 0xe6e30000 0x0 0x8>;
			clocks = <0x3 0x1 0x20b>;
			power-domains = <0x1 0x20>;
			resets = <0x3 0x20b>;
			#pwm-cells = <0x2>;
			status = "disabled";
		};

		pwm@e6e31000 {
			compatible = "renesas,pwm-r8a7795", "renesas,pwm-rcar";
			reg = <0x0 0xe6e31000 0x0 0x8>;
			clocks = <0x3 0x1 0x20b>;
			power-domains = <0x1 0x20>;
			resets = <0x3 0x20b>;
			#pwm-cells = <0x2>;
			status = "disabled";
		};

		pwm@e6e32000 {
			compatible = "renesas,pwm-r8a7795", "renesas,pwm-rcar";
			reg = <0x0 0xe6e32000 0x0 0x8>;
			clocks = <0x3 0x1 0x20b>;
			power-domains = <0x1 0x20>;
			resets = <0x3 0x20b>;
			#pwm-cells = <0x2>;
			status = "disabled";
		};

		pwm@e6e33000 {
			compatible = "renesas,pwm-r8a7795", "renesas,pwm-rcar";
			reg = <0x0 0xe6e33000 0x0 0x8>;
			clocks = <0x3 0x1 0x20b>;
			power-domains = <0x1 0x20>;
			resets = <0x3 0x20b>;
			#pwm-cells = <0x2>;
			status = "disabled";
		};

		pwm@e6e34000 {
			compatible = "renesas,pwm-r8a7795", "renesas,pwm-rcar";
			reg = <0x0 0xe6e34000 0x0 0x8>;
			clocks = <0x3 0x1 0x20b>;
			power-domains = <0x1 0x20>;
			resets = <0x3 0x20b>;
			#pwm-cells = <0x2>;
			status = "disabled";
		};

		pwm@e6e35000 {
			compatible = "renesas,pwm-r8a7795", "renesas,pwm-rcar";
			reg = <0x0 0xe6e35000 0x0 0x8>;
			clocks = <0x3 0x1 0x20b>;
			power-domains = <0x1 0x20>;
			resets = <0x3 0x20b>;
			#pwm-cells = <0x2>;
			status = "disabled";
		};

		pwm@e6e36000 {
			compatible = "renesas,pwm-r8a7795", "renesas,pwm-rcar";
			reg = <0x0 0xe6e36000 0x0 0x8>;
			clocks = <0x3 0x1 0x20b>;
			power-domains = <0x1 0x20>;
			resets = <0x3 0x20b>;
			#pwm-cells = <0x2>;
			status = "disabled";
		};

		serial@e6e60000 {
			compatible = "renesas,scif-r8a7795", "renesas,rcar-gen3-scif", "renesas,scif";
			reg = <0x0 0xe6e60000 0x0 0x40>;
			interrupts = <0x0 0x98 0x4>;
			clocks = <0x3 0x1 0xcf 0x3 0x0 0x10 0x1f>;
			clock-names = "fck", "brg_int", "scif_clk";
			dmas = <0x14 0x51 0x14 0x50 0x15 0x51 0x15 0x50>;
			dma-names = "tx", "rx", "tx", "rx";
			power-domains = <0x1 0x20>;
			resets = <0x3 0xcf>;
			status = "disabled";
		};

		serial@e6e68000 {
			compatible = "renesas,scif-r8a7795", "renesas,rcar-gen3-scif", "renesas,scif";
			reg = <0x0 0xe6e68000 0x0 0x40>;
			interrupts = <0x0 0x99 0x4>;
			clocks = <0x3 0x1 0xce 0x3 0x0 0x10 0x1f>;
			clock-names = "fck", "brg_int", "scif_clk";
			dmas = <0x14 0x53 0x14 0x52 0x15 0x53 0x15 0x52>;
			dma-names = "tx", "rx", "tx", "rx";
			power-domains = <0x1 0x20>;
			resets = <0x3 0xce>;
			status = "disabled";
		};

		serial@e6e88000 {
			compatible = "renesas,scif-r8a7795", "renesas,rcar-gen3-scif", "renesas,scif";
			reg = <0x0 0xe6e88000 0x0 0x40>;
			interrupts = <0x0 0xa4 0x4>;
			clocks = <0x3 0x1 0x136 0x3 0x0 0x10 0x1f>;
			clock-names = "fck", "brg_int", "scif_clk";
			dmas = <0x14 0x13 0x14 0x12 0x15 0x13 0x15 0x12>;
			dma-names = "tx", "rx", "tx", "rx";
			power-domains = <0x1 0x20>;
			resets = <0x3 0x136>;
			status = "okay";
			pinctrl-0 = <0x2f>;
			pinctrl-names = "default";
		};

		serial@e6c50000 {
			compatible = "renesas,scif-r8a7795", "renesas,rcar-gen3-scif", "renesas,scif";
			reg = <0x0 0xe6c50000 0x0 0x40>;
			interrupts = <0x0 0x17 0x4>;
			clocks = <0x3 0x1 0xcc 0x3 0x0 0x10 0x1f>;
			clock-names = "fck", "brg_int", "scif_clk";
			dmas = <0x1b 0x57 0x1b 0x56>;
			dma-names = "tx", "rx";
			power-domains = <0x1 0x20>;
			resets = <0x3 0xcc>;
			status = "disabled";
		};

		serial@e6c40000 {
			compatible = "renesas,scif-r8a7795", "renesas,rcar-gen3-scif", "renesas,scif";
			reg = <0x0 0xe6c40000 0x0 0x40>;
			interrupts = <0x0 0x10 0x4>;
			clocks = <0x3 0x1 0xcb 0x3 0x0 0x10 0x1f>;
			clock-names = "fck", "brg_int", "scif_clk";
			dmas = <0x1b 0x59 0x1b 0x58>;
			dma-names = "tx", "rx";
			power-domains = <0x1 0x20>;
			resets = <0x3 0xcb>;
			status = "disabled";
		};

		serial@e6f30000 {
			compatible = "renesas,scif-r8a7795", "renesas,rcar-gen3-scif", "renesas,scif";
			reg = <0x0 0xe6f30000 0x0 0x40>;
			interrupts = <0x0 0x11 0x4>;
			clocks = <0x3 0x1 0xca 0x3 0x0 0x10 0x1f>;
			clock-names = "fck", "brg_int", "scif_clk";
			dmas = <0x14 0x5b 0x14 0x5a 0x15 0x5b 0x15 0x5a>;
			dma-names = "tx", "rx", "tx", "rx";
			power-domains = <0x1 0x20>;
			resets = <0x3 0xca>;
			status = "disabled";
		};

		spi@e6e90000 {
			compatible = "renesas,msiof-r8a7795", "renesas,rcar-gen3-msiof";
			reg = <0x0 0xe6e90000 0x0 0x64>;
			interrupts = <0x0 0x9c 0x4>;
			clocks = <0x3 0x1 0xd3>;
			dmas = <0x14 0x41 0x14 0x40 0x15 0x41 0x15 0x40>;
			dma-names = "tx", "rx", "tx", "rx";
			power-domains = <0x1 0x20>;
			resets = <0x3 0xd3>;
			#address-cells = <0x1>;
			#size-cells = <0x0>;
			status = "disabled";
		};

		spi@e6ea0000 {
			compatible = "renesas,msiof-r8a7795", "renesas,rcar-gen3-msiof";
			reg = <0x0 0xe6ea0000 0x0 0x64>;
			interrupts = <0x0 0x9d 0x4>;
			clocks = <0x3 0x1 0xd2>;
			dmas = <0x14 0x43 0x14 0x42 0x15 0x43 0x15 0x42>;
			dma-names = "tx", "rx", "tx", "rx";
			power-domains = <0x1 0x20>;
			resets = <0x3 0xd2>;
			#address-cells = <0x1>;
			#size-cells = <0x0>;
			status = "disabled";
		};

		spi@e6c00000 {
			compatible = "renesas,msiof-r8a7795", "renesas,rcar-gen3-msiof";
			reg = <0x0 0xe6c00000 0x0 0x64>;
			interrupts = <0x0 0x9e 0x4>;
			clocks = <0x3 0x1 0xd1>;
			dmas = <0x1b 0x45 0x1b 0x44>;
			dma-names = "tx", "rx";
			power-domains = <0x1 0x20>;
			resets = <0x3 0xd1>;
			#address-cells = <0x1>;
			#size-cells = <0x0>;
			status = "disabled";
		};

		spi@e6c10000 {
			compatible = "renesas,msiof-r8a7795", "renesas,rcar-gen3-msiof";
			reg = <0x0 0xe6c10000 0x0 0x64>;
			interrupts = <0x0 0x9f 0x4>;
			clocks = <0x3 0x1 0xd0>;
			dmas = <0x1b 0x47 0x1b 0x46>;
			dma-names = "tx", "rx";
			power-domains = <0x1 0x20>;
			resets = <0x3 0xd0>;
			#address-cells = <0x1>;
			#size-cells = <0x0>;
			status = "disabled";
		};

		video@e6ef0000 {
			compatible = "renesas,vin-r8a7795";
			reg = <0x0 0xe6ef0000 0x0 0x1000>;
			interrupts = <0x0 0xbc 0x4>;
			clocks = <0x3 0x1 0x32b>;
			power-domains = <0x1 0x20>;
			resets = <0x3 0x32b>;
			renesas,id = <0x0>;
			status = "disabled";

			ports {
				#address-cells = <0x1>;
				#size-cells = <0x0>;

				port@1 {
					#address-cells = <0x1>;
					#size-cells = <0x0>;
					reg = <0x1>;

					endpoint@0 {
						reg = <0x0>;
						remote-endpoint = <0x30>;
						phandle = <0x74>;
					};

					endpoint@2 {
						reg = <0x2>;
						remote-endpoint = <0x31>;
						phandle = <0x7c>;
					};
				};
			};
		};

		video@e6ef1000 {
			compatible = "renesas,vin-r8a7795";
			reg = <0x0 0xe6ef1000 0x0 0x1000>;
			interrupts = <0x0 0xbd 0x4>;
			clocks = <0x3 0x1 0x32a>;
			power-domains = <0x1 0x20>;
			resets = <0x3 0x32a>;
			renesas,id = <0x1>;
			status = "disabled";

			ports {
				#address-cells = <0x1>;
				#size-cells = <0x0>;

				port@1 {
					#address-cells = <0x1>;
					#size-cells = <0x0>;
					reg = <0x1>;

					endpoint@0 {
						reg = <0x0>;
						remote-endpoint = <0x32>;
						phandle = <0x75>;
					};

					endpoint@2 {
						reg = <0x2>;
						remote-endpoint = <0x33>;
						phandle = <0x7d>;
					};
				};
			};
		};

		video@e6ef2000 {
			compatible = "renesas,vin-r8a7795";
			reg = <0x0 0xe6ef2000 0x0 0x1000>;
			interrupts = <0x0 0xbe 0x4>;
			clocks = <0x3 0x1 0x329>;
			power-domains = <0x1 0x20>;
			resets = <0x3 0x329>;
			renesas,id = <0x2>;
			status = "disabled";

			ports {
				#address-cells = <0x1>;
				#size-cells = <0x0>;

				port@1 {
					#address-cells = <0x1>;
					#size-cells = <0x0>;
					reg = <0x1>;

					endpoint@0 {
						reg = <0x0>;
						remote-endpoint = <0x34>;
						phandle = <0x76>;
					};

					endpoint@2 {
						reg = <0x2>;
						remote-endpoint = <0x35>;
						phandle = <0x7e>;
					};
				};
			};
		};

		video@e6ef3000 {
			compatible = "renesas,vin-r8a7795";
			reg = <0x0 0xe6ef3000 0x0 0x1000>;
			interrupts = <0x0 0xbf 0x4>;
			clocks = <0x3 0x1 0x328>;
			power-domains = <0x1 0x20>;
			resets = <0x3 0x328>;
			renesas,id = <0x3>;
			status = "disabled";

			ports {
				#address-cells = <0x1>;
				#size-cells = <0x0>;

				port@1 {
					#address-cells = <0x1>;
					#size-cells = <0x0>;
					reg = <0x1>;

					endpoint@0 {
						reg = <0x0>;
						remote-endpoint = <0x36>;
						phandle = <0x77>;
					};

					endpoint@2 {
						reg = <0x2>;
						remote-endpoint = <0x37>;
						phandle = <0x7f>;
					};
				};
			};
		};

		video@e6ef4000 {
			compatible = "renesas,vin-r8a7795";
			reg = <0x0 0xe6ef4000 0x0 0x1000>;
			interrupts = <0x0 0xae 0x4>;
			clocks = <0x3 0x1 0x327>;
			power-domains = <0x1 0x20>;
			resets = <0x3 0x327>;
			renesas,id = <0x4>;
			status = "disabled";

			ports {
				#address-cells = <0x1>;
				#size-cells = <0x0>;

				port@1 {
					#address-cells = <0x1>;
					#size-cells = <0x0>;
					reg = <0x1>;

					endpoint@0 {
						reg = <0x0>;
						remote-endpoint = <0x38>;
						phandle = <0x78>;
					};

					endpoint@3 {
						reg = <0x3>;
						remote-endpoint = <0x39>;
						phandle = <0x80>;
					};
				};
			};
		};

		video@e6ef5000 {
			compatible = "renesas,vin-r8a7795";
			reg = <0x0 0xe6ef5000 0x0 0x1000>;
			interrupts = <0x0 0xaf 0x4>;
			clocks = <0x3 0x1 0x326>;
			power-domains = <0x1 0x20>;
			resets = <0x3 0x326>;
			renesas,id = <0x5>;
			status = "disabled";

			ports {
				#address-cells = <0x1>;
				#size-cells = <0x0>;

				port@1 {
					#address-cells = <0x1>;
					#size-cells = <0x0>;
					reg = <0x1>;

					endpoint@0 {
						reg = <0x0>;
						remote-endpoint = <0x3a>;
						phandle = <0x79>;
					};

					endpoint@3 {
						reg = <0x3>;
						remote-endpoint = <0x3b>;
						phandle = <0x81>;
					};
				};
			};
		};

		video@e6ef6000 {
			compatible = "renesas,vin-r8a7795";
			reg = <0x0 0xe6ef6000 0x0 0x1000>;
			interrupts = <0x0 0xb0 0x4>;
			clocks = <0x3 0x1 0x325>;
			power-domains = <0x1 0x20>;
			resets = <0x3 0x325>;
			renesas,id = <0x6>;
			status = "disabled";

			ports {
				#address-cells = <0x1>;
				#size-cells = <0x0>;

				port@1 {
					#address-cells = <0x1>;
					#size-cells = <0x0>;
					reg = <0x1>;

					endpoint@0 {
						reg = <0x0>;
						remote-endpoint = <0x3c>;
						phandle = <0x7a>;
					};

					endpoint@3 {
						reg = <0x3>;
						remote-endpoint = <0x3d>;
						phandle = <0x82>;
					};
				};
			};
		};

		video@e6ef7000 {
			compatible = "renesas,vin-r8a7795";
			reg = <0x0 0xe6ef7000 0x0 0x1000>;
			interrupts = <0x0 0xab 0x4>;
			clocks = <0x3 0x1 0x324>;
			power-domains = <0x1 0x20>;
			resets = <0x3 0x324>;
			renesas,id = <0x7>;
			status = "disabled";

			ports {
				#address-cells = <0x1>;
				#size-cells = <0x0>;

				port@1 {
					#address-cells = <0x1>;
					#size-cells = <0x0>;
					reg = <0x1>;

					endpoint@0 {
						reg = <0x0>;
						remote-endpoint = <0x3e>;
						phandle = <0x7b>;
					};

					endpoint@3 {
						reg = <0x3>;
						remote-endpoint = <0x3f>;
						phandle = <0x83>;
					};
				};
			};
		};

		rif@e6f40000 {
			compatible = "renesas,r8a7795-drif", "renesas,rcar-gen3-drif";
			reg = <0x0 0xe6f40000 0x0 0x64>;
			interrupts = <0x0 0xc 0x4>;
			clocks = <0x3 0x1 0x203>;
			clock-names = "fck";
			dmas = <0x14 0x20 0x15 0x20>;
			dma-names = "rx", "rx";
			power-domains = <0x1 0x20>;
			resets = <0x3 0x203>;
			renesas,bonding = <0x40>;
			status = "disabled";
			phandle = <0x41>;
		};

		rif@e6f50000 {
			compatible = "renesas,r8a7795-drif", "renesas,rcar-gen3-drif";
			reg = <0x0 0xe6f50000 0x0 0x64>;
			interrupts = <0x0 0xd 0x4>;
			clocks = <0x3 0x1 0x202>;
			clock-names = "fck";
			dmas = <0x14 0x22 0x15 0x22>;
			dma-names = "rx", "rx";
			power-domains = <0x1 0x20>;
			resets = <0x3 0x202>;
			renesas,bonding = <0x41>;
			status = "disabled";
			phandle = <0x40>;
		};

		rif@e6f60000 {
			compatible = "renesas,r8a7795-drif", "renesas,rcar-gen3-drif";
			reg = <0x0 0xe6f60000 0x0 0x64>;
			interrupts = <0x0 0xe 0x4>;
			clocks = <0x3 0x1 0x201>;
			clock-names = "fck";
			dmas = <0x14 0x24 0x15 0x24>;
			dma-names = "rx", "rx";
			power-domains = <0x1 0x20>;
			resets = <0x3 0x201>;
			renesas,bonding = <0x42>;
			status = "disabled";
			phandle = <0x43>;
		};

		rif@e6f70000 {
			compatible = "renesas,r8a7795-drif", "renesas,rcar-gen3-drif";
			reg = <0x0 0xe6f70000 0x0 0x64>;
			interrupts = <0x0 0xf 0x4>;
			clocks = <0x3 0x1 0x200>;
			clock-names = "fck";
			dmas = <0x14 0x26 0x15 0x26>;
			dma-names = "rx", "rx";
			power-domains = <0x1 0x20>;
			resets = <0x3 0x200>;
			renesas,bonding = <0x43>;
			status = "disabled";
			phandle = <0x42>;
		};

		rif@e6f80000 {
			compatible = "renesas,r8a7795-drif", "renesas,rcar-gen3-drif";
			reg = <0x0 0xe6f80000 0x0 0x64>;
			interrupts = <0x0 0x18 0x4>;
			clocks = <0x3 0x1 0x1ff>;
			clock-names = "fck";
			dmas = <0x14 0x28 0x15 0x28>;
			dma-names = "rx", "rx";
			power-domains = <0x1 0x20>;
			resets = <0x3 0x1ff>;
			renesas,bonding = <0x44>;
			status = "disabled";
			phandle = <0x45>;
		};

		rif@e6f90000 {
			compatible = "renesas,r8a7795-drif", "renesas,rcar-gen3-drif";
			reg = <0x0 0xe6f90000 0x0 0x64>;
			interrupts = <0x0 0x19 0x4>;
			clocks = <0x3 0x1 0x1fe>;
			clock-names = "fck";
			dmas = <0x14 0x2a 0x15 0x2a>;
			dma-names = "rx", "rx";
			power-domains = <0x1 0x20>;
			resets = <0x3 0x1fe>;
			renesas,bonding = <0x45>;
			status = "disabled";
			phandle = <0x44>;
		};

		rif@e6fa0000 {
			compatible = "renesas,r8a7795-drif", "renesas,rcar-gen3-drif";
			reg = <0x0 0xe6fa0000 0x0 0x64>;
			interrupts = <0x0 0x1a 0x4>;
			clocks = <0x3 0x1 0x1fd>;
			clock-names = "fck";
			dmas = <0x14 0x2c 0x15 0x2c>;
			dma-names = "rx", "rx";
			power-domains = <0x1 0x20>;
			resets = <0x3 0x1fd>;
			renesas,bonding = <0x46>;
			status = "disabled";
			phandle = <0x47>;
		};

		rif@e6fb0000 {
			compatible = "renesas,r8a7795-drif", "renesas,rcar-gen3-drif";
			reg = <0x0 0xe6fb0000 0x0 0x64>;
			interrupts = <0x0 0x1b 0x4>;
			clocks = <0x3 0x1 0x1fc>;
			clock-names = "fck";
			dmas = <0x14 0x2e 0x15 0x2e>;
			dma-names = "rx", "rx";
			power-domains = <0x1 0x20>;
			resets = <0x3 0x1fc>;
			renesas,bonding = <0x47>;
			status = "disabled";
			phandle = <0x46>;
		};

		sound@ec500000 {
			compatible = "renesas,rcar_sound-r8a7795", "renesas,rcar_sound-gen3";
			reg = <0x0 0xec500000 0x0 0x1000 0x0 0xec5a0000 0x0 0x100 0x0 0xec540000 0x0 0x1000 0x0 0xec541000 0x0 0x280 0x0 0xec740000 0x0 0x200>;
			reg-names = "scu", "adg", "ssiu", "ssi", "audmapp";
			clocks = <0x3 0x1 0x3ed 0x3 0x1 0x3ee 0x3 0x1 0x3ef 0x3 0x1 0x3f0 0x3 0x1 0x3f1 0x3 0x1 0x3f2 0x3 0x1 0x3f3 0x3 0x1 0x3f4 0x3 0x1 0x3f5 0x3 0x1 0x3f6 0x3 0x1 0x3f7 0x3 0x1 0x3fe 0x3 0x1 0x3ff 0x3 0x1 0x400 0x3 0x1 0x401 0x3 0x1 0x402 0x3 0x1 0x403 0x3 0x1 0x404 0x3 0x1 0x405 0x3 0x1 0x406 0x3 0x1 0x407 0x3 0x1 0x3fc 0x3 0x1 0x3fd 0x3 0x1 0x3fc 0x3 0x1 0x3fd 0x3 0x1 0x3fb 0x3 0x1 0x3fa 0x48 0x1a 0x49 0x3 0x0 0x9>;
			clock-names = "ssi-all", "ssi.9", "ssi.8", "ssi.7", "ssi.6", "ssi.5", "ssi.4", "ssi.3", "ssi.2", "ssi.1", "ssi.0", "src.9", "src.8", "src.7", "src.6", "src.5", "src.4", "src.3", "src.2", "src.1", "src.0", "mix.1", "mix.0", "ctu.1", "ctu.0", "dvc.0", "dvc.1", "clk_a", "clk_b", "clk_c", "clk_i";
			power-domains = <0x1 0x20>;
			resets = <0x3 0x3ed 0x3 0x3ee 0x3 0x3ef 0x3 0x3f0 0x3 0x3f1 0x3 0x3f2 0x3 0x3f3 0x3 0x3f4 0x3 0x3f5 0x3 0x3f6 0x3 0x3f7>;
			reset-names = "ssi-all", "ssi.9", "ssi.8", "ssi.7", "ssi.6", "ssi.5", "ssi.4", "ssi.3", "ssi.2", "ssi.1", "ssi.0";
			status = "okay";
			pinctrl-0 = <0x4a 0x4b>;
			pinctrl-names = "default";
			#sound-dai-cells = <0x0>;
			#clock-cells = <0x1>;
			clock-frequency = <0xbb8000 0xac4400>;
			phandle = <0x17>;

			rcar_sound,dvc {

				dvc-0 {
					dmas = <0x4c 0xbc>;
					dma-names = "tx";
					phandle = <0x50>;
				};

				dvc-1 {
					dmas = <0x4c 0xbe>;
					dma-names = "tx";
					phandle = <0x53>;
				};
			};

			rcar_sound,mix {

				mix-0 {
				};

				mix-1 {
				};
			};

			rcar_sound,ctu {

				ctu-0 {
				};

				ctu-1 {
				};

				ctu-2 {
				};

				ctu-3 {
				};

				ctu-4 {
				};

				ctu-5 {
				};

				ctu-6 {
				};

				ctu-7 {
				};
			};

			rcar_sound,src {

				src-0 {
					interrupts = <0x0 0x160 0x4>;
					dmas = <0x4d 0x85 0x4c 0x9a>;
					dma-names = "rx", "tx";
					phandle = <0x4f>;
				};

				src-1 {
					interrupts = <0x0 0x161 0x4>;
					dmas = <0x4d 0x87 0x4c 0x9c>;
					dma-names = "rx", "tx";
					phandle = <0x52>;
				};

				src-2 {
					interrupts = <0x0 0x162 0x4>;
					dmas = <0x4d 0x89 0x4c 0x9e>;
					dma-names = "rx", "tx";
				};

				src-3 {
					interrupts = <0x0 0x163 0x4>;
					dmas = <0x4d 0x8b 0x4c 0xa0>;
					dma-names = "rx", "tx";
				};

				src-4 {
					interrupts = <0x0 0x164 0x4>;
					dmas = <0x4d 0x8d 0x4c 0xb0>;
					dma-names = "rx", "tx";
				};

				src-5 {
					interrupts = <0x0 0x165 0x4>;
					dmas = <0x4d 0x8f 0x4c 0xb2>;
					dma-names = "rx", "tx";
				};

				src-6 {
					interrupts = <0x0 0x166 0x4>;
					dmas = <0x4d 0x91 0x4c 0xb4>;
					dma-names = "rx", "tx";
				};

				src-7 {
					interrupts = <0x0 0x167 0x4>;
					dmas = <0x4d 0x93 0x4c 0xb6>;
					dma-names = "rx", "tx";
				};

				src-8 {
					interrupts = <0x0 0x168 0x4>;
					dmas = <0x4d 0x95 0x4c 0xb8>;
					dma-names = "rx", "tx";
				};

				src-9 {
					interrupts = <0x0 0x169 0x4>;
					dmas = <0x4d 0x97 0x4c 0xba>;
					dma-names = "rx", "tx";
				};
			};

			rcar_sound,ssi {

				ssi-0 {
					interrupts = <0x0 0x172 0x4>;
					dmas = <0x4d 0x1 0x4c 0x2 0x4d 0x15 0x4c 0x16>;
					dma-names = "rx", "tx", "rxu", "txu";
					phandle = <0x4e>;
				};

				ssi-1 {
					interrupts = <0x0 0x173 0x4>;
					dmas = <0x4d 0x3 0x4c 0x4 0x4d 0x49 0x4c 0x4a>;
					dma-names = "rx", "tx", "rxu", "txu";
					shared-pin;
					phandle = <0x51>;
				};

				ssi-2 {
					interrupts = <0x0 0x174 0x4>;
					dmas = <0x4d 0x5 0x4c 0x6 0x4d 0x63 0x4c 0x64>;
					dma-names = "rx", "tx", "rxu", "txu";
				};

				ssi-3 {
					interrupts = <0x0 0x175 0x4>;
					dmas = <0x4d 0x7 0x4c 0x8 0x4d 0x6f 0x4c 0x70>;
					dma-names = "rx", "tx", "rxu", "txu";
				};

				ssi-4 {
					interrupts = <0x0 0x176 0x4>;
					dmas = <0x4d 0x9 0x4c 0xa 0x4d 0x71 0x4c 0x72>;
					dma-names = "rx", "tx", "rxu", "txu";
				};

				ssi-5 {
					interrupts = <0x0 0x177 0x4>;
					dmas = <0x4d 0xb 0x4c 0xc 0x4d 0x73 0x4c 0x74>;
					dma-names = "rx", "tx", "rxu", "txu";
				};

				ssi-6 {
					interrupts = <0x0 0x178 0x4>;
					dmas = <0x4d 0xd 0x4c 0xe 0x4d 0x75 0x4c 0x76>;
					dma-names = "rx", "tx", "rxu", "txu";
				};

				ssi-7 {
					interrupts = <0x0 0x179 0x4>;
					dmas = <0x4d 0xf 0x4c 0x10 0x4d 0x79 0x4c 0x7a>;
					dma-names = "rx", "tx", "rxu", "txu";
				};

				ssi-8 {
					interrupts = <0x0 0x17a 0x4>;
					dmas = <0x4d 0x11 0x4c 0x12 0x4d 0x7b 0x4c 0x7c>;
					dma-names = "rx", "tx", "rxu", "txu";
				};

				ssi-9 {
					interrupts = <0x0 0x17b 0x4>;
					dmas = <0x4d 0x13 0x4c 0x14 0x4d 0x7d 0x4c 0x7e>;
					dma-names = "rx", "tx", "rxu", "txu";
				};
			};

			ports {
				#address-cells = <0x1>;
				#size-cells = <0x0>;

				port@0 {
					reg = <0x0>;
				};

				port@1 {
					reg = <0x1>;
				};

				port@2 {
					reg = <0x2>;
				};
			};

			rcar_sound,dai {

				dai0 {
					playback = <0x4e 0x4f 0x50>;
					capture = <0x51 0x52 0x53>;
				};
			};
		};

		dma-controller@ec700000 {
			compatible = "renesas,dmac-r8a7795", "renesas,rcar-dmac";
			reg = <0x0 0xec700000 0x0 0x10000>;
			interrupts = <0x0 0x15e 0x4 0x0 0x140 0x4 0x0 0x141 0x4 0x0 0x142 0x4 0x0 0x143 0x4 0x0 0x144 0x4 0x0 0x145 0x4 0x0 0x146 0x4 0x0 0x147 0x4 0x0 0x148 0x4 0x0 0x149 0x4 0x0 0x14a 0x4 0x0 0x14b 0x4 0x0 0x14c 0x4 0x0 0x14d 0x4 0x0 0x14e 0x4 0x0 0x14f 0x4>;
			interrupt-names = "error", "ch0", "ch1", "ch2", "ch3", "ch4", "ch5", "ch6", "ch7", "ch8", "ch9", "ch10", "ch11", "ch12", "ch13", "ch14", "ch15";
			clocks = <0x3 0x1 0x1f6>;
			clock-names = "fck";
			power-domains = <0x1 0x20>;
			resets = <0x3 0x1f6>;
			#dma-cells = <0x1>;
			dma-channels = <0x10>;
			iommus = <0x54 0x0 0x54 0x1 0x54 0x2 0x54 0x3 0x54 0x4 0x54 0x5 0x54 0x6 0x54 0x7 0x54 0x8 0x54 0x9 0x54 0xa 0x54 0xb 0x54 0xc 0x54 0xd 0x54 0xe 0x54 0xf>;
			phandle = <0x4d>;
		};

		dma-controller@ec720000 {
			compatible = "renesas,dmac-r8a7795", "renesas,rcar-dmac";
			reg = <0x0 0xec720000 0x0 0x10000>;
			interrupts = <0x0 0x15f 0x4 0x0 0x150 0x4 0x0 0x151 0x4 0x0 0x152 0x4 0x0 0x153 0x4 0x0 0x154 0x4 0x0 0x155 0x4 0x0 0x156 0x4 0x0 0x157 0x4 0x0 0x158 0x4 0x0 0x159 0x4 0x0 0x15a 0x4 0x0 0x15b 0x4 0x0 0x15c 0x4 0x0 0x15d 0x4 0x0 0x17e 0x4 0x0 0x17f 0x4>;
			interrupt-names = "error", "ch0", "ch1", "ch2", "ch3", "ch4", "ch5", "ch6", "ch7", "ch8", "ch9", "ch10", "ch11", "ch12", "ch13", "ch14", "ch15";
			clocks = <0x3 0x1 0x1f5>;
			clock-names = "fck";
			power-domains = <0x1 0x20>;
			resets = <0x3 0x1f5>;
			#dma-cells = <0x1>;
			dma-channels = <0x10>;
			iommus = <0x54 0x10 0x54 0x11 0x54 0x12 0x54 0x13 0x54 0x14 0x54 0x15 0x54 0x16 0x54 0x17 0x54 0x18 0x54 0x19 0x54 0x1a 0x54 0x1b 0x54 0x1c 0x54 0x1d 0x54 0x1e 0x54 0x1f>;
			phandle = <0x4c>;
		};

		usb@ee000000 {
			compatible = "renesas,xhci-r8a7795", "renesas,rcar-gen3-xhci";
			reg = <0x0 0xee000000 0x0 0xc00>;
			interrupts = <0x0 0x66 0x4>;
			clocks = <0x3 0x1 0x148>;
			power-domains = <0x1 0x20>;
			resets = <0x3 0x148>;
			status = "disabled";
		};

		usb@ee020000 {
			compatible = "renesas,r8a7795-usb3-peri", "renesas,rcar-gen3-usb3-peri";
			reg = <0x0 0xee020000 0x0 0x400>;
			interrupts = <0x0 0x68 0x4>;
			clocks = <0x3 0x1 0x148>;
			power-domains = <0x1 0x20>;
			resets = <0x3 0x148>;
			status = "disabled";
		};

		usb@ee080000 {
			compatible = "generic-ohci";
			reg = <0x0 0xee080000 0x0 0x100>;
			interrupts = <0x0 0x6c 0x4>;
			clocks = <0x3 0x1 0x2bf 0x3 0x1 0x2c0>;
			phys = <0x22>;
			phy-names = "usb";
			power-domains = <0x1 0x20>;
			resets = <0x3 0x2bf 0x3 0x2c0>;
			status = "disabled";
			phandle = <0x57>;
		};

		usb@ee0a0000 {
			compatible = "generic-ohci";
			reg = <0x0 0xee0a0000 0x0 0x100>;
			interrupts = <0x0 0x70 0x4>;
			clocks = <0x3 0x1 0x2be>;
			phys = <0x55>;
			phy-names = "usb";
			power-domains = <0x1 0x20>;
			resets = <0x3 0x2be>;
			status = "okay";
			phandle = <0x58>;
		};

		usb@ee0c0000 {
			compatible = "generic-ohci";
			reg = <0x0 0xee0c0000 0x0 0x100>;
			interrupts = <0x0 0x71 0x4>;
			clocks = <0x3 0x1 0x2bd>;
			phys = <0x56>;
			phy-names = "usb";
			power-domains = <0x1 0x20>;
			resets = <0x3 0x2bd>;
			status = "disabled";
			phandle = <0x59>;
		};

		usb@ee0e0000 {
			compatible = "generic-ohci";
			reg = <0x0 0xee0e0000 0x0 0x100>;
			interrupts = <0x0 0x24 0x4>;
			clocks = <0x3 0x1 0x2bc 0x3 0x1 0x2c1>;
			phys = <0x25>;
			phy-names = "usb";
			power-domains = <0x1 0x20>;
			resets = <0x3 0x2bc 0x3 0x2c1>;
			status = "disabled";
			phandle = <0x5a>;
		};

		usb@ee080100 {
			compatible = "generic-ehci";
			reg = <0x0 0xee080100 0x0 0x100>;
			interrupts = <0x0 0x6c 0x4>;
			clocks = <0x3 0x1 0x2bf 0x3 0x1 0x2c0>;
			phys = <0x22>;
			phy-names = "usb";
			companion = <0x57>;
			power-domains = <0x1 0x20>;
			resets = <0x3 0x2bf 0x3 0x2c0>;
			status = "disabled";
		};

		usb@ee0a0100 {
			compatible = "generic-ehci";
			reg = <0x0 0xee0a0100 0x0 0x100>;
			interrupts = <0x0 0x70 0x4>;
			clocks = <0x3 0x1 0x2be>;
			phys = <0x55>;
			phy-names = "usb";
			companion = <0x58>;
			power-domains = <0x1 0x20>;
			resets = <0x3 0x2be>;
			status = "okay";
		};

		usb@ee0c0100 {
			compatible = "generic-ehci";
			reg = <0x0 0xee0c0100 0x0 0x100>;
			interrupts = <0x0 0x71 0x4>;
			clocks = <0x3 0x1 0x2bd>;
			phys = <0x56>;
			phy-names = "usb";
			companion = <0x59>;
			power-domains = <0x1 0x20>;
			resets = <0x3 0x2bd>;
			status = "disabled";
		};

		usb@ee0e0100 {
			compatible = "generic-ehci";
			reg = <0x0 0xee0e0100 0x0 0x100>;
			interrupts = <0x0 0x24 0x4>;
			clocks = <0x3 0x1 0x2bc 0x3 0x1 0x2c1>;
			phys = <0x25>;
			phy-names = "usb";
			companion = <0x5a>;
			power-domains = <0x1 0x20>;
			resets = <0x3 0x2bc 0x3 0x2c1>;
			status = "disabled";
		};

		usb-phy@ee080200 {
			compatible = "renesas,usb2-phy-r8a7795", "renesas,rcar-gen3-usb2-phy";
			reg = <0x0 0xee080200 0x0 0x700>;
			interrupts = <0x0 0x6c 0x4>;
			clocks = <0x3 0x1 0x2bf 0x3 0x1 0x2c0>;
			power-domains = <0x1 0x20>;
			resets = <0x3 0x2bf 0x3 0x2c0>;
			#phy-cells = <0x0>;
			status = "disabled";
			phandle = <0x22>;
		};

		usb-phy@ee0a0200 {
			compatible = "renesas,usb2-phy-r8a7795", "renesas,rcar-gen3-usb2-phy";
			reg = <0x0 0xee0a0200 0x0 0x700>;
			clocks = <0x3 0x1 0x2be>;
			power-domains = <0x1 0x20>;
			resets = <0x3 0x2be>;
			#phy-cells = <0x0>;
			status = "okay";
			pinctrl-0 = <0x5b>;
			pinctrl-names = "default";
			phandle = <0x55>;
		};

		usb-phy@ee0c0200 {
			compatible = "renesas,usb2-phy-r8a7795", "renesas,rcar-gen3-usb2-phy";
			reg = <0x0 0xee0c0200 0x0 0x700>;
			clocks = <0x3 0x1 0x2bd>;
			power-domains = <0x1 0x20>;
			resets = <0x3 0x2bd>;
			#phy-cells = <0x0>;
			status = "disabled";
			phandle = <0x56>;
		};

		usb-phy@ee0e0200 {
			compatible = "renesas,usb2-phy-r8a7795", "renesas,rcar-gen3-usb2-phy";
			reg = <0x0 0xee0e0200 0x0 0x700>;
			interrupts = <0x0 0x24 0x4>;
			clocks = <0x3 0x1 0x2bc 0x3 0x1 0x2c1>;
			power-domains = <0x1 0x20>;
			resets = <0x3 0x2bc 0x3 0x2c1>;
			#phy-cells = <0x0>;
			status = "disabled";
			phandle = <0x25>;
		};

		sd@ee100000 {
			compatible = "renesas,sdhi-r8a7795", "renesas,rcar-gen3-sdhi";
			reg = <0x0 0xee100000 0x0 0x2000>;
			interrupts = <0x0 0xa5 0x4>;
			clocks = <0x3 0x1 0x13a>;
			max-frequency = <0xbebc200>;
			power-domains = <0x1 0x20>;
			resets = <0x3 0x13a>;
			status = "okay";
			pinctrl-0 = <0x5c>;
			pinctrl-1 = <0x5d>;
			pinctrl-names = "default", "state_uhs";
			vmmc-supply = <0x5e>;
			vqmmc-supply = <0x5f>;
			cd-gpios = <0x60 0xc 0x1>;
			bus-width = <0x4>;
			sd-uhs-sdr50;
			sd-uhs-sdr104;
		};

		sd@ee120000 {
			compatible = "renesas,sdhi-r8a7795", "renesas,rcar-gen3-sdhi";
			reg = <0x0 0xee120000 0x0 0x2000>;
			interrupts = <0x0 0xa6 0x4>;
			clocks = <0x3 0x1 0x139>;
			max-frequency = <0xbebc200>;
			power-domains = <0x1 0x20>;
			resets = <0x3 0x139>;
			status = "disabled";
		};

		sd@ee140000 {
			compatible = "renesas,sdhi-r8a7795", "renesas,rcar-gen3-sdhi";
			reg = <0x0 0xee140000 0x0 0x2000>;
			interrupts = <0x0 0xa7 0x4>;
			clocks = <0x3 0x1 0x138>;
			max-frequency = <0xbebc200>;
			power-domains = <0x1 0x20>;
			resets = <0x3 0x138>;
			status = "okay";
			pinctrl-0 = <0x61>;
			pinctrl-1 = <0x62>;
			pinctrl-names = "default", "state_uhs";
			vmmc-supply = <0x63>;
			vqmmc-supply = <0x64>;
			bus-width = <0x8>;
			mmc-hs200-1_8v;
			non-removable;
		};

		sd@ee160000 {
			compatible = "renesas,sdhi-r8a7795", "renesas,rcar-gen3-sdhi";
			reg = <0x0 0xee160000 0x0 0x2000>;
			interrupts = <0x0 0xa8 0x4>;
			clocks = <0x3 0x1 0x137>;
			max-frequency = <0xbebc200>;
			power-domains = <0x1 0x20>;
			resets = <0x3 0x137>;
			status = "disabled";
		};

		sata@ee300000 {
			compatible = "renesas,sata-r8a7795", "renesas,rcar-gen3-sata";
			reg = <0x0 0xee300000 0x0 0x200000>;
			interrupts = <0x0 0x69 0x4>;
			clocks = <0x3 0x1 0x32f>;
			power-domains = <0x1 0x20>;
			resets = <0x3 0x32f>;
			status = "disabled";
			iommus = <0x65 0x2>;
		};

		interrupt-controller@f1010000 {
			compatible = "arm,gic-400";
			#interrupt-cells = <0x3>;
			#address-cells = <0x0>;
			interrupt-controller;
			reg = <0x0 0xf1010000 0x0 0x1000 0x0 0xf1020000 0x0 0x20000 0x0 0xf1040000 0x0 0x20000 0x0 0xf1060000 0x0 0x20000>;
			interrupts = <0x1 0x9 0xff04>;
			clocks = <0x3 0x1 0x198>;
			clock-names = "clk";
			power-domains = <0x1 0x20>;
			resets = <0x3 0x198>;
			phandle = <0x7>;
		};

		pcie@fe000000 {
			compatible = "renesas,pcie-r8a7795", "renesas,pcie-rcar-gen3";
			reg = <0x0 0xfe000000 0x0 0x80000>;
			#address-cells = <0x3>;
			#size-cells = <0x2>;
			bus-range = <0x0 0xff>;
			device_type = "pci";
			ranges = <0x1000000 0x0 0x0 0x0 0xfe100000 0x0 0x100000 0x2000000 0x0 0xfe200000 0x0 0xfe200000 0x0 0x200000 0x2000000 0x0 0x30000000 0x0 0x30000000 0x0 0x8000000 0x42000000 0x0 0x38000000 0x0 0x38000000 0x0 0x8000000>;
			dma-ranges = <0x42000000 0x0 0x40000000 0x0 0x40000000 0x0 0x40000000>;
			interrupts = <0x0 0x74 0x4 0x0 0x75 0x4 0x0 0x76 0x4>;
			#interrupt-cells = <0x1>;
			interrupt-map-mask = <0x0 0x0 0x0 0x0>;
			interrupt-map = <0x0 0x0 0x0 0x0 0x7 0x0 0x74 0x4>;
			clocks = <0x3 0x1 0x13f 0x66>;
			clock-names = "pcie", "pcie_bus";
			power-domains = <0x1 0x20>;
			resets = <0x3 0x13f>;
			status = "disabled";
		};

		pcie@ee800000 {
			compatible = "renesas,pcie-r8a7795", "renesas,pcie-rcar-gen3";
			reg = <0x0 0xee800000 0x0 0x80000>;
			#address-cells = <0x3>;
			#size-cells = <0x2>;
			bus-range = <0x0 0xff>;
			device_type = "pci";
			ranges = <0x1000000 0x0 0x0 0x0 0xee900000 0x0 0x100000 0x2000000 0x0 0xeea00000 0x0 0xeea00000 0x0 0x200000 0x2000000 0x0 0xc0000000 0x0 0xc0000000 0x0 0x8000000 0x42000000 0x0 0xc8000000 0x0 0xc8000000 0x0 0x8000000>;
			dma-ranges = <0x42000000 0x0 0x40000000 0x0 0x40000000 0x0 0x40000000>;
			interrupts = <0x0 0x94 0x4 0x0 0x95 0x4 0x0 0x96 0x4>;
			#interrupt-cells = <0x1>;
			interrupt-map-mask = <0x0 0x0 0x0 0x0>;
			interrupt-map = <0x0 0x0 0x0 0x0 0x7 0x0 0x94 0x4>;
			clocks = <0x3 0x1 0x13e 0x66>;
			clock-names = "pcie", "pcie_bus";
			power-domains = <0x1 0x20>;
			resets = <0x3 0x13e>;
			status = "disabled";
		};

		imr-lx4@fe860000 {
			compatible = "renesas,r8a7795-imr-lx4", "renesas,imr-lx4";
			reg = <0x0 0xfe860000 0x0 0x2000>;
			interrupts = <0x0 0xc0 0x4>;
			clocks = <0x3 0x1 0x337>;
			power-domains = <0x1 0xe>;
			resets = <0x3 0x337>;
		};

		imr-lx4@fe870000 {
			compatible = "renesas,r8a7795-imr-lx4", "renesas,imr-lx4";
			reg = <0x0 0xfe870000 0x0 0x2000>;
			interrupts = <0x0 0xc1 0x4>;
			clocks = <0x3 0x1 0x336>;
			power-domains = <0x1 0xe>;
			resets = <0x3 0x336>;
		};

		imr-lx4@fe880000 {
			compatible = "renesas,r8a7795-imr-lx4", "renesas,imr-lx4";
			reg = <0x0 0xfe880000 0x0 0x2000>;
			interrupts = <0x0 0xc2 0x4>;
			clocks = <0x3 0x1 0x335>;
			power-domains = <0x1 0xe>;
			resets = <0x3 0x335>;
		};

		imr-lx4@fe890000 {
			compatible = "renesas,r8a7795-imr-lx4", "renesas,imr-lx4";
			reg = <0x0 0xfe890000 0x0 0x2000>;
			interrupts = <0x0 0xc3 0x4>;
			clocks = <0x3 0x1 0x334>;
			power-domains = <0x1 0xe>;
			resets = <0x3 0x334>;
		};

		fdp1@fe940000 {
			compatible = "renesas,fdp1";
			reg = <0x0 0xfe940000 0x0 0x2400>;
			interrupts = <0x0 0x106 0x4>;
			clocks = <0x3 0x1 0x77>;
			power-domains = <0x1 0x9>;
			resets = <0x3 0x77>;
			renesas,fcp = <0x67>;
		};

		fdp1@fe944000 {
			compatible = "renesas,fdp1";
			reg = <0x0 0xfe944000 0x0 0x2400>;
			interrupts = <0x0 0x107 0x4>;
			clocks = <0x3 0x1 0x76>;
			power-domains = <0x1 0x9>;
			resets = <0x3 0x76>;
			renesas,fcp = <0x68>;
		};

		fcp@fe950000 {
			compatible = "renesas,fcpf";
			reg = <0x0 0xfe950000 0x0 0x200>;
			clocks = <0x3 0x1 0x267>;
			power-domains = <0x1 0x9>;
			resets = <0x3 0x267>;
			iommus = <0x69 0x0>;
			phandle = <0x67>;
		};

		fcp@fe951000 {
			compatible = "renesas,fcpf";
			reg = <0x0 0xfe951000 0x0 0x200>;
			clocks = <0x3 0x1 0x266>;
			power-domains = <0x1 0x9>;
			resets = <0x3 0x266>;
			iommus = <0x6a 0x1>;
			phandle = <0x68>;
		};

		fcp@fe96f000 {
			compatible = "renesas,fcpv";
			reg = <0x0 0xfe96f000 0x0 0x200>;
			clocks = <0x3 0x1 0x25f>;
			power-domains = <0x1 0x9>;
			resets = <0x3 0x25f>;
			iommus = <0x69 0x5>;
			phandle = <0x6d>;
		};

		fcp@fe92f000 {
			compatible = "renesas,fcpv";
			reg = <0x0 0xfe92f000 0x0 0x200>;
			clocks = <0x3 0x1 0x25e>;
			power-domains = <0x1 0x9>;
			resets = <0x3 0x25e>;
			iommus = <0x6a 0x7>;
			phandle = <0x6e>;
		};

		fcp@fe9af000 {
			compatible = "renesas,fcpv";
			reg = <0x0 0xfe9af000 0x0 0x200>;
			clocks = <0x3 0x1 0x263>;
			power-domains = <0x1 0x9>;
			resets = <0x3 0x263>;
			iommus = <0x69 0x8>;
			phandle = <0x72>;
		};

		fcp@fe9bf000 {
			compatible = "renesas,fcpv";
			reg = <0x0 0xfe9bf000 0x0 0x200>;
			clocks = <0x3 0x1 0x262>;
			power-domains = <0x1 0x9>;
			resets = <0x3 0x262>;
			iommus = <0x6a 0x9>;
			phandle = <0x73>;
		};

		fcp@fea27000 {
			compatible = "renesas,fcpv";
			reg = <0x0 0xfea27000 0x0 0x200>;
			clocks = <0x3 0x1 0x25b>;
			power-domains = <0x1 0x20>;
			resets = <0x3 0x25b>;
			iommus = <0x6b 0x8>;
			phandle = <0x6f>;
		};

		fcp@fea2f000 {
			compatible = "renesas,fcpv";
			reg = <0x0 0xfea2f000 0x0 0x200>;
			clocks = <0x3 0x1 0x25a>;
			power-domains = <0x1 0x20>;
			resets = <0x3 0x25a>;
			iommus = <0x6b 0x9>;
			phandle = <0x70>;
		};

		fcp@fea37000 {
			compatible = "renesas,fcpv";
			reg = <0x0 0xfea37000 0x0 0x200>;
			clocks = <0x3 0x1 0x259>;
			power-domains = <0x1 0x20>;
			resets = <0x3 0x259>;
			iommus = <0x6c 0xa>;
			phandle = <0x71>;
		};

		vsp@fe960000 {
			compatible = "renesas,vsp2";
			reg = <0x0 0xfe960000 0x0 0x8000>;
			interrupts = <0x0 0x10a 0x4>;
			clocks = <0x3 0x1 0x272>;
			power-domains = <0x1 0x9>;
			resets = <0x3 0x272>;
			renesas,fcp = <0x6d>;
		};

		vsp@fe920000 {
			compatible = "renesas,vsp2";
			reg = <0x0 0xfe920000 0x0 0x8000>;
			interrupts = <0x0 0x1d1 0x4>;
			clocks = <0x3 0x1 0x270>;
			power-domains = <0x1 0x9>;
			resets = <0x3 0x270>;
			renesas,fcp = <0x6e>;
		};

		vsp@fea20000 {
			compatible = "renesas,vsp2";
			reg = <0x0 0xfea20000 0x0 0x5000>;
			interrupts = <0x0 0x1d2 0x4>;
			clocks = <0x3 0x1 0x26f>;
			power-domains = <0x1 0x20>;
			resets = <0x3 0x26f>;
			renesas,fcp = <0x6f>;
			phandle = <0x88>;
		};

		vsp@fea28000 {
			compatible = "renesas,vsp2";
			reg = <0x0 0xfea28000 0x0 0x5000>;
			interrupts = <0x0 0x1d3 0x4>;
			clocks = <0x3 0x1 0x26e>;
			power-domains = <0x1 0x20>;
			resets = <0x3 0x26e>;
			renesas,fcp = <0x70>;
			phandle = <0x89>;
		};

		vsp@fea30000 {
			compatible = "renesas,vsp2";
			reg = <0x0 0xfea30000 0x0 0x5000>;
			interrupts = <0x0 0x1d4 0x4>;
			clocks = <0x3 0x1 0x26d>;
			power-domains = <0x1 0x20>;
			resets = <0x3 0x26d>;
			renesas,fcp = <0x71>;
			phandle = <0x8a>;
		};

		vsp@fe9a0000 {
			compatible = "renesas,vsp2";
			reg = <0x0 0xfe9a0000 0x0 0x8000>;
			interrupts = <0x0 0x1bc 0x4>;
			clocks = <0x3 0x1 0x277>;
			power-domains = <0x1 0x9>;
			resets = <0x3 0x277>;
			renesas,fcp = <0x72>;
		};

		vsp@fe9b0000 {
			compatible = "renesas,vsp2";
			reg = <0x0 0xfe9b0000 0x0 0x8000>;
			interrupts = <0x0 0x1bd 0x4>;
			clocks = <0x3 0x1 0x276>;
			power-domains = <0x1 0x9>;
			resets = <0x3 0x276>;
			renesas,fcp = <0x73>;
		};

		csi2@fea80000 {
			compatible = "renesas,r8a7795-csi2";
			reg = <0x0 0xfea80000 0x0 0x10000>;
			interrupts = <0x0 0xb8 0x4>;
			clocks = <0x3 0x1 0x2ca>;
			power-domains = <0x1 0x20>;
			resets = <0x3 0x2ca>;
			status = "disabled";

			ports {
				#address-cells = <0x1>;
				#size-cells = <0x0>;

				port@1 {
					#address-cells = <0x1>;
					#size-cells = <0x0>;
					reg = <0x1>;

					endpoint@0 {
						reg = <0x0>;
						remote-endpoint = <0x74>;
						phandle = <0x30>;
					};

					endpoint@1 {
						reg = <0x1>;
						remote-endpoint = <0x75>;
						phandle = <0x32>;
					};

					endpoint@2 {
						reg = <0x2>;
						remote-endpoint = <0x76>;
						phandle = <0x34>;
					};

					endpoint@3 {
						reg = <0x3>;
						remote-endpoint = <0x77>;
						phandle = <0x36>;
					};

					endpoint@4 {
						reg = <0x4>;
						remote-endpoint = <0x78>;
						phandle = <0x38>;
					};

					endpoint@5 {
						reg = <0x5>;
						remote-endpoint = <0x79>;
						phandle = <0x3a>;
					};

					endpoint@6 {
						reg = <0x6>;
						remote-endpoint = <0x7a>;
						phandle = <0x3c>;
					};

					endpoint@7 {
						reg = <0x7>;
						remote-endpoint = <0x7b>;
						phandle = <0x3e>;
					};
				};
			};
		};

		csi2@feaa0000 {
			compatible = "renesas,r8a7795-csi2";
			reg = <0x0 0xfeaa0000 0x0 0x10000>;
			interrupts = <0x0 0xf6 0x4>;
			clocks = <0x3 0x1 0x2cc>;
			power-domains = <0x1 0x20>;
			resets = <0x3 0x2cc>;
			status = "disabled";

			ports {
				#address-cells = <0x1>;
				#size-cells = <0x0>;

				port@1 {
					#address-cells = <0x1>;
					#size-cells = <0x0>;
					reg = <0x1>;

					endpoint@0 {
						reg = <0x0>;
						remote-endpoint = <0x7c>;
						phandle = <0x31>;
					};

					endpoint@1 {
						reg = <0x1>;
						remote-endpoint = <0x7d>;
						phandle = <0x33>;
					};

					endpoint@2 {
						reg = <0x2>;
						remote-endpoint = <0x7e>;
						phandle = <0x35>;
					};

					endpoint@3 {
						reg = <0x3>;
						remote-endpoint = <0x7f>;
						phandle = <0x37>;
					};
				};
			};
		};

		csi2@feab0000 {
			compatible = "renesas,r8a7795-csi2";
			reg = <0x0 0xfeab0000 0x0 0x10000>;
			interrupts = <0x0 0xf7 0x4>;
			clocks = <0x3 0x1 0x2cb>;
			power-domains = <0x1 0x20>;
			resets = <0x3 0x2cb>;
			status = "disabled";

			ports {
				#address-cells = <0x1>;
				#size-cells = <0x0>;

				port@1 {
					#address-cells = <0x1>;
					#size-cells = <0x0>;
					reg = <0x1>;

					endpoint@0 {
						reg = <0x0>;
						remote-endpoint = <0x80>;
						phandle = <0x39>;
					};

					endpoint@1 {
						reg = <0x1>;
						remote-endpoint = <0x81>;
						phandle = <0x3b>;
					};

					endpoint@2 {
						reg = <0x2>;
						remote-endpoint = <0x82>;
						phandle = <0x3d>;
					};

					endpoint@3 {
						reg = <0x3>;
						remote-endpoint = <0x83>;
						phandle = <0x3f>;
					};
				};
			};
		};

		hdmi@fead0000 {
			compatible = "renesas,r8a7795-hdmi", "renesas,rcar-gen3-hdmi";
			reg = <0x0 0xfead0000 0x0 0x10000>;
			interrupts = <0x0 0x185 0x4>;
			clocks = <0x3 0x1 0x2d9 0x3 0x0 0x28>;
			clock-names = "iahb", "isfr";
			power-domains = <0x1 0x20>;
			resets = <0x3 0x2d9>;
			status = "okay";

			ports {
				#address-cells = <0x1>;
				#size-cells = <0x0>;

				port@0 {
					reg = <0x0>;

					endpoint {
						remote-endpoint = <0x84>;
						phandle = <0x8b>;
					};
				};

				port@1 {
					reg = <0x1>;

					endpoint {
						remote-endpoint = <0x85>;
						phandle = <0x93>;
					};
				};

				port@2 {
					reg = <0x2>;
				};
			};
		};

		hdmi@feae0000 {
			compatible = "renesas,r8a7795-hdmi", "renesas,rcar-gen3-hdmi";
			reg = <0x0 0xfeae0000 0x0 0x10000>;
			interrupts = <0x0 0x1b4 0x4>;
			clocks = <0x3 0x1 0x2d8 0x3 0x0 0x28>;
			clock-names = "iahb", "isfr";
			power-domains = <0x1 0x20>;
			resets = <0x3 0x2d8>;
			status = "disabled";

			ports {
				#address-cells = <0x1>;
				#size-cells = <0x0>;

				port@0 {
					reg = <0x0>;

					endpoint {
						remote-endpoint = <0x86>;
						phandle = <0x8c>;
					};
				};

				port@1 {
					reg = <0x1>;
				};

				port@2 {
					reg = <0x2>;
				};
			};
		};

		display@feb00000 {
			compatible = "renesas,du-r8a7795";
			reg = <0x0 0xfeb00000 0x0 0x80000>;
			interrupts = <0x0 0x100 0x4 0x0 0x10c 0x4 0x0 0x10d 0x4 0x0 0x10e 0x4>;
			clocks = <0x3 0x1 0x2d4 0x3 0x1 0x2d3 0x3 0x1 0x2d2 0x3 0x1 0x2d1 0x87 0x1 0x87 0x3 0x87 0x4 0x87 0x2>;
			clock-names = "du.0", "du.1", "du.2", "du.3", "dclkin.0", "dclkin.1", "dclkin.2", "dclkin.3";
			vsps = <0x88 0x0 0x89 0x0 0x8a 0x0 0x88 0x1>;
			status = "okay";

			ports {
				#address-cells = <0x1>;
				#size-cells = <0x0>;

				port@0 {
					reg = <0x0>;

					endpoint {
					};
				};

				port@1 {
					reg = <0x1>;

					endpoint {
						remote-endpoint = <0x8b>;
						phandle = <0x84>;
					};
				};

				port@2 {
					reg = <0x2>;

					endpoint {
						remote-endpoint = <0x8c>;
						phandle = <0x86>;
					};
				};

				port@3 {
					reg = <0x3>;

					endpoint {
						remote-endpoint = <0x8d>;
						phandle = <0x8e>;
					};
				};
			};
		};

		lvds@feb90000 {
			compatible = "renesas,r8a7795-lvds";
			reg = <0x0 0xfeb90000 0x0 0x14>;
			clocks = <0x3 0x1 0x2d7>;
			power-domains = <0x1 0x20>;
			resets = <0x3 0x2d7>;
			status = "disabled";

			ports {
				#address-cells = <0x1>;
				#size-cells = <0x0>;

				port@0 {
					reg = <0x0>;

					endpoint {
						remote-endpoint = <0x8e>;
						phandle = <0x8d>;
					};
				};

				port@1 {
					reg = <0x1>;

					endpoint {
					};
				};
			};
		};

		chipid@fff00044 {
			compatible = "renesas,prr";
			reg = <0x0 0xfff00044 0x0 0x4>;
		};
	};

	thermal-zones {

		sensor-thermal1 {
			polling-delay-passive = <0xfa>;
			polling-delay = <0x3e8>;
			thermal-sensors = <0x8f 0x0>;

			trips {

				sensor1-passive {
					temperature = <0x17318>;
					hysteresis = <0x3e8>;
					type = "passive";
					phandle = <0x90>;
				};

				sensor1-crit {
					temperature = <0x1d4c0>;
					hysteresis = <0x3e8>;
					type = "critical";
				};
			};

			cooling-maps {

				map0 {
					trip = <0x90>;
					cooling-device = <0xc 0x4 0x4>;
				};
			};
		};

		sensor-thermal2 {
			polling-delay-passive = <0xfa>;
			polling-delay = <0x3e8>;
			thermal-sensors = <0x8f 0x1>;

			trips {

				sensor2-passive {
					temperature = <0x17318>;
					hysteresis = <0x3e8>;
					type = "passive";
					phandle = <0x91>;
				};

				sensor2-crit {
					temperature = <0x1d4c0>;
					hysteresis = <0x3e8>;
					type = "critical";
				};
			};

			cooling-maps {

				map0 {
					trip = <0x91>;
					cooling-device = <0xc 0x4 0x4>;
				};
			};
		};

		sensor-thermal3 {
			polling-delay-passive = <0xfa>;
			polling-delay = <0x3e8>;
			thermal-sensors = <0x8f 0x2>;

			trips {

				sensor3-passive {
					temperature = <0x17318>;
					hysteresis = <0x3e8>;
					type = "passive";
					phandle = <0x92>;
				};

				sensor3-crit {
					temperature = <0x1d4c0>;
					hysteresis = <0x3e8>;
					type = "critical";
				};
			};

			cooling-maps {

				map0 {
					trip = <0x92>;
					cooling-device = <0xc 0x4 0x4>;
				};
			};
		};
	};

	timer {
		compatible = "arm,armv8-timer";
		interrupts-extended = <0x7 0x1 0xd 0xff08 0x7 0x1 0xe 0xff08 0x7 0x1 0xb 0xff08 0x7 0x1 0xa 0xff08>;
	};

	usb3s0 {
		compatible = "fixed-clock";
		#clock-cells = <0x0>;
		clock-frequency = <0x0>;
		phandle = <0x26>;
	};

	usb_extal {
		compatible = "fixed-clock";
		#clock-cells = <0x0>;
		clock-frequency = <0x0>;
		phandle = <0x27>;
	};

	chosen {
		bootargs = "ignore_loglevel rw root=/dev/nfs ip=dhcp";
		stdout-path = "serial0:115200n8";
	};

	audio-clkout {
		compatible = "fixed-clock";
		#clock-cells = <0x0>;
		clock-frequency = <0xbb8000>;
		phandle = <0x18>;
	};

	hdmi0-out {
		compatible = "hdmi-connector";
		type = [61 00];

		port {

			endpoint {
				remote-endpoint = <0x93>;
				phandle = <0x85>;
			};
		};
	};

	keyboard {
		compatible = "gpio-keys";

		key-1 {
			linux,code = <0x2>;
			label = "SW3";
			wakeup-source;
			debounce-interval = <0x14>;
			gpios = <0x94 0xb 0x1>;
		};
	};

	leds {
		compatible = "gpio-leds";

		led5 {
			gpios = <0x94 0xc 0x0>;
		};

		led6 {
			gpios = <0x94 0xd 0x0>;
		};
	};

	regulator0 {
		compatible = "regulator-fixed";
		regulator-name = "fixed-1.8V";
		regulator-min-microvolt = <0x1b7740>;
		regulator-max-microvolt = <0x1b7740>;
		regulator-boot-on;
		regulator-always-on;
		phandle = <0x64>;
	};

	regulator1 {
		compatible = "regulator-fixed";
		regulator-name = "fixed-3.3V";
		regulator-min-microvolt = <0x325aa0>;
		regulator-max-microvolt = <0x325aa0>;
		regulator-boot-on;
		regulator-always-on;
		phandle = <0x63>;
	};

	sound {
		compatible = "simple-audio-card";
		simple-audio-card,format = "left_j";
		simple-audio-card,bitclock-master = <0x95>;
		simple-audio-card,frame-master = <0x95>;

		simple-audio-card,cpu {
			sound-dai = <0x17>;
			phandle = <0x95>;
		};

		simple-audio-card,codec {
			sound-dai = <0x96>;
		};
	};

	regulator-vcc-sdhi0 {
		compatible = "regulator-fixed";
		regulator-name = "SDHI0 Vcc";
		regulator-min-microvolt = <0x325aa0>;
		regulator-max-microvolt = <0x325aa0>;
		gpio = <0x97 0x2 0x0>;
		enable-active-high;
		phandle = <0x5e>;
	};

	regulator-vccq-sdhi0 {
		compatible = "regulator-gpio";
		regulator-name = "SDHI0 VccQ";
		regulator-min-microvolt = <0x1b7740>;
		regulator-max-microvolt = <0x325aa0>;
		gpios = <0x97 0x1 0x0>;
		gpios-states = <0x1>;
		states = <0x325aa0 0x1 0x1b7740 0x0>;
		phandle = <0x5f>;
	};

	x12 {
		compatible = "fixed-clock";
		#clock-cells = <0x0>;
		clock-frequency = <0x1770000>;
		phandle = <0x19>;
	};

	x23-clock {
		compatible = "fixed-clock";
		#clock-cells = <0x0>;
		clock-frequency = <0x17d7840>;
		phandle = <0x1c>;
	};

	memory@48000000 {
		device_type = "memory";
		reg = <0x0 0x48000000 0x0 0x38000000>;
	};

	memory@500000000 {
		device_type = "memory";
		reg = <0x5 0x0 0x0 0x40000000>;
	};

	memory@600000000 {
		device_type = "memory";
		reg = <0x6 0x0 0x0 0x40000000>;
	};

	memory@700000000 {
		device_type = "memory";
		reg = <0x7 0x0 0x0 0x40000000>;
	};
};
